AUTOSAR XML (schema 3.1.2)
package /Components/SWC_AFAT
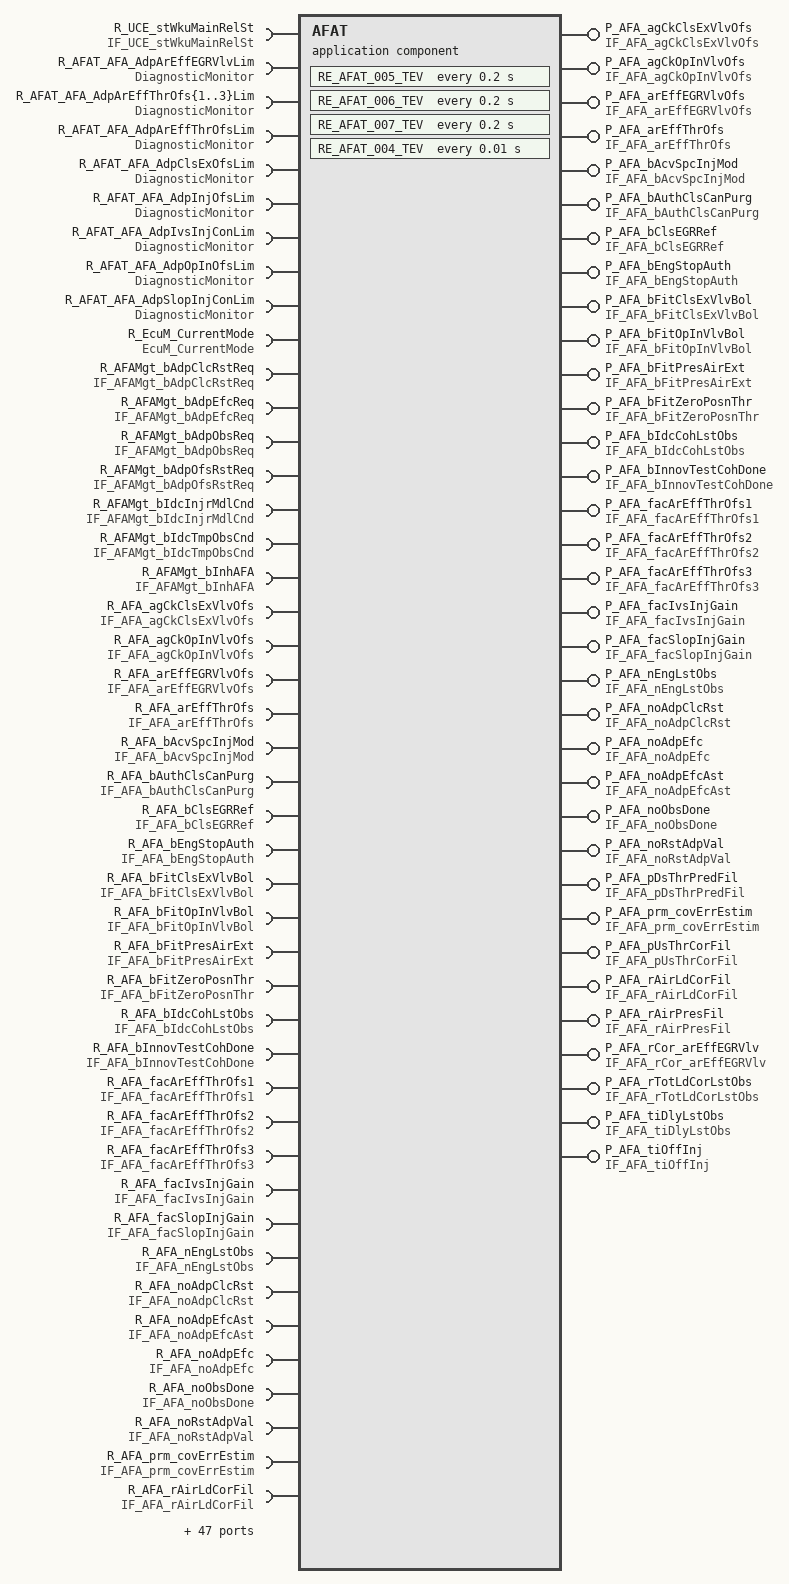
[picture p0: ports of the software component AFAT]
  application software component type AFAT
    11 x require port:
      R_UCE_stWkuMainRelSt: required-interface=IF_UCE_stWkuMainRelSt
      R_AFAT_AFA_AdpArEffEGRVlvLim: required-interface=DiagnosticMonitor
      R_AFAT_AFA_AdpArEffThrOfs{1..3}Lim: required-interface=DiagnosticMonitor
      R_AFAT_AFA_AdpArEffThrOfsLim: required-interface=DiagnosticMonitor
      R_AFAT_AFA_AdpClsExOfsLim: required-interface=DiagnosticMonitor
      R_AFAT_AFA_AdpInjOfsLim: required-interface=DiagnosticMonitor
      R_AFAT_AFA_AdpIvsInjConLim: required-interface=DiagnosticMonitor
      R_AFAT_AFA_AdpOpInOfsLim: required-interface=DiagnosticMonitor
      R_AFAT_AFA_AdpSlopInjConLim: required-interface=DiagnosticMonitor
    34 x provide port:
      P_AFA_agCkClsExVlvOfs: unqueued-sender-com-spec{data-element=AFA_agCkClsExVlvOfs, can-invalidate=false, init-value=SInt8InitValue}, provided-interface=IF_AFA_agCkClsExVlvOfs
      P_AFA_agCkOpInVlvOfs: unqueued-sender-com-spec{data-element=AFA_agCkOpInVlvOfs, can-invalidate=false, init-value=SInt8InitValue1}, provided-interface=IF_AFA_agCkOpInVlvOfs
      P_AFA_arEffEGRVlvOfs: unqueued-sender-com-spec{data-element=AFA_arEffEGRVlvOfs, can-invalidate=false, init-value=SInt8InitValue3}, provided-interface=IF_AFA_arEffEGRVlvOfs
      P_AFA_arEffThrOfs: unqueued-sender-com-spec{data-element=AFA_arEffThrOfs, can-invalidate=false, init-value=SInt16InitValue}, provided-interface=IF_AFA_arEffThrOfs
      P_AFA_bAcvSpcInjMod: unqueued-sender-com-spec{data-element=AFA_bAcvSpcInjMod, can-invalidate=false, init-value=BooleanInitValue}, provided-interface=IF_AFA_bAcvSpcInjMod
      P_AFA_bAuthClsCanPurg: unqueued-sender-com-spec{data-element=AFA_bAuthClsCanPurg, can-invalidate=false, init-value=BooleanInitValue5}, provided-interface=IF_AFA_bAuthClsCanPurg
      P_AFA_bClsEGRRef: unqueued-sender-com-spec{data-element=AFA_bClsEGRRef, can-invalidate=false, init-value=BooleanInitValue7}, provided-interface=IF_AFA_bClsEGRRef
      P_AFA_bEngStopAuth: unqueued-sender-com-spec{data-element=AFA_bEngStopAuth, can-invalidate=false, init-value=BooleanInitValue9}, provided-interface=IF_AFA_bEngStopAuth
      P_AFA_bFitClsExVlvBol: unqueued-sender-com-spec{data-element=AFA_bFitClsExVlvBol, can-invalidate=false, init-value=BooleanInitValue11}, provided-interface=IF_AFA_bFitClsExVlvBol
      P_AFA_bFitOpInVlvBol: unqueued-sender-com-spec{data-element=AFA_bFitOpInVlvBol, can-invalidate=false, init-value=BooleanInitValue13}, provided-interface=IF_AFA_bFitOpInVlvBol
      P_AFA_bFitPresAirExt: unqueued-sender-com-spec{data-element=AFA_bFitPresAirExt, can-invalidate=false, init-value=BooleanInitValue15}, provided-interface=IF_AFA_bFitPresAirExt
      P_AFA_bFitZeroPosnThr: unqueued-sender-com-spec{data-element=AFA_bFitZeroPosnThr, can-invalidate=false, init-value=BooleanInitValue17}, provided-interface=IF_AFA_bFitZeroPosnThr
      P_AFA_bIdcCohLstObs: unqueued-sender-com-spec{data-element=AFA_bIdcCohLstObs, can-invalidate=false, init-value=BooleanInitValue19}, provided-interface=IF_AFA_bIdcCohLstObs
      P_AFA_bInnovTestCohDone: unqueued-sender-com-spec{data-element=AFA_bInnovTestCohDone, can-invalidate=false, init-value=BooleanInitValue21}, provided-interface=IF_AFA_bInnovTestCohDone
      P_AFA_facArEffThrOfs1: unqueued-sender-com-spec{data-element=AFA_facArEffThrOfs1, can-invalidate=false, init-value=SInt8InitValue23}, provided-interface=IF_AFA_facArEffThrOfs1
      P_AFA_facArEffThrOfs2: unqueued-sender-com-spec{data-element=AFA_facArEffThrOfs2, can-invalidate=false, init-value=SInt8InitValue25}, provided-interface=IF_AFA_facArEffThrOfs2
      P_AFA_facArEffThrOfs3: unqueued-sender-com-spec{data-element=AFA_facArEffThrOfs3, can-invalidate=false, init-value=SInt8InitValue27}, provided-interface=IF_AFA_facArEffThrOfs3
      P_AFA_facIvsInjGain: unqueued-sender-com-spec{data-element=AFA_facIvsInjGain, can-invalidate=false, init-value=SInt16InitValue29}, provided-interface=IF_AFA_facIvsInjGain
      P_AFA_facSlopInjGain: unqueued-sender-com-spec{data-element=AFA_facSlopInjGain, can-invalidate=false, init-value=SInt32InitValue}, provided-interface=IF_AFA_facSlopInjGain
      P_AFA_nEngLstObs: unqueued-sender-com-spec{data-element=AFA_nEngLstObs, can-invalidate=false, init-value=UInt16InitValue}, provided-interface=IF_AFA_nEngLstObs
      P_AFA_noAdpClcRst: unqueued-sender-com-spec{data-element=AFA_noAdpClcRst, can-invalidate=false, init-value=UInt8InitValue}, provided-interface=IF_AFA_noAdpClcRst
      P_AFA_noAdpEfc: unqueued-sender-com-spec{data-element=AFA_noAdpEfc, can-invalidate=false, init-value=UInt16InitValue31}, provided-interface=IF_AFA_noAdpEfc
      P_AFA_noAdpEfcAst: unqueued-sender-com-spec{data-element=AFA_noAdpEfcAst, can-invalidate=false, init-value=UInt16InitValue33}, provided-interface=IF_AFA_noAdpEfcAst
      P_AFA_noObsDone: unqueued-sender-com-spec{data-element=AFA_noObsDone, can-invalidate=false, init-value=UInt8InitValue35}, provided-interface=IF_AFA_noObsDone
      P_AFA_noRstAdpVal: unqueued-sender-com-spec{data-element=AFA_noRstAdpVal, can-invalidate=false, init-value=UInt8InitValue37}, provided-interface=IF_AFA_noRstAdpVal
      P_AFA_pDsThrPredFil: unqueued-sender-com-spec{data-element=AFA_pDsThrPredFil, can-invalidate=false, init-value=UInt16InitValue39}, provided-interface=IF_AFA_pDsThrPredFil
      P_AFA_prm_covErrEstim: unqueued-sender-com-spec{data-element=AFA_prm_covErrEstim, can-invalidate=false, init-value=rt_Array_UInt16_8InitValue}, provided-interface=IF_AFA_prm_covErrEstim
      P_AFA_pUsThrCorFil: unqueued-sender-com-spec{data-element=AFA_pUsThrCorFil, can-invalidate=false, init-value=UInt16InitValue41}, provided-interface=IF_AFA_pUsThrCorFil
      P_AFA_rAirLdCorFil: unqueued-sender-com-spec{data-element=AFA_rAirLdCorFil, can-invalidate=false, init-value=UInt16InitValue43}, provided-interface=IF_AFA_rAirLdCorFil
      P_AFA_rAirPresFil: unqueued-sender-com-spec{data-element=AFA_rAirPresFil, can-invalidate=false, init-value=UInt16InitValue45}, provided-interface=IF_AFA_rAirPresFil
      P_AFA_rCor_arEffEGRVlv: unqueued-sender-com-spec{data-element=AFA_rCor_arEffEGRVlv, can-invalidate=false, init-value=SInt8InitValue47}, provided-interface=IF_AFA_rCor_arEffEGRVlv
      P_AFA_rTotLdCorLstObs: unqueued-sender-com-spec{data-element=AFA_rTotLdCorLstObs, can-invalidate=false, init-value=UInt16InitValue49}, provided-interface=IF_AFA_rTotLdCorLstObs
      P_AFA_tiDlyLstObs: unqueued-sender-com-spec{data-element=AFA_tiDlyLstObs, can-invalidate=false, init-value=UInt32InitValue}, provided-interface=IF_AFA_tiDlyLstObs
      P_AFA_tiOffInj: unqueued-sender-com-spec{data-element=AFA_tiOffInj, can-invalidate=false, init-value=SInt8InitValue51}, provided-interface=IF_AFA_tiOffInj
    82 x require port:
      R_EcuM_CurrentMode: required-interface=EcuM_CurrentMode
      R_AFAMgt_bAdpClcRstReq: unqueued-receiver-com-spec{data-element=AFAMgt_bAdpClcRstReq, init-value=BooleanInitValue53, resync-time=0}, required-interface=IF_AFAMgt_bAdpClcRstReq
      R_AFAMgt_bAdpEfcReq: unqueued-receiver-com-spec{data-element=AFAMgt_bAdpEfcReq, init-value=BooleanInitValue55, resync-time=0}, required-interface=IF_AFAMgt_bAdpEfcReq
      R_AFAMgt_bAdpObsReq: unqueued-receiver-com-spec{data-element=AFAMgt_bAdpObsReq, init-value=BooleanInitValue57, resync-time=0}, required-interface=IF_AFAMgt_bAdpObsReq
      R_AFAMgt_bAdpOfsRstReq: unqueued-receiver-com-spec{data-element=AFAMgt_bAdpOfsRstReq, init-value=BooleanInitValue59, resync-time=0}, required-interface=IF_AFAMgt_bAdpOfsRstReq
      R_AFAMgt_bIdcInjrMdlCnd: unqueued-receiver-com-spec{data-element=AFAMgt_bIdcInjrMdlCnd, init-value=BooleanInitValue61, resync-time=0}, required-interface=IF_AFAMgt_bIdcInjrMdlCnd
      R_AFAMgt_bIdcTmpObsCnd: unqueued-receiver-com-spec{data-element=AFAMgt_bIdcTmpObsCnd, init-value=BooleanInitValue63, resync-time=0}, required-interface=IF_AFAMgt_bIdcTmpObsCnd
      R_AFAMgt_bInhAFA: unqueued-receiver-com-spec{data-element=AFAMgt_bInhAFA, init-value=BooleanInitValue65, resync-time=0}, required-interface=IF_AFAMgt_bInhAFA
      R_AFA_agCkClsExVlvOfs: unqueued-receiver-com-spec{data-element=AFA_agCkClsExVlvOfs, init-value=SInt8InitValue, resync-time=0}, required-interface=IF_AFA_agCkClsExVlvOfs
      R_AFA_agCkOpInVlvOfs: unqueued-receiver-com-spec{data-element=AFA_agCkOpInVlvOfs, init-value=SInt8InitValue67, resync-time=0}, required-interface=IF_AFA_agCkOpInVlvOfs
      R_AFA_arEffEGRVlvOfs: unqueued-receiver-com-spec{data-element=AFA_arEffEGRVlvOfs, init-value=SInt8InitValue69, resync-time=0}, required-interface=IF_AFA_arEffEGRVlvOfs
      R_AFA_arEffThrOfs: unqueued-receiver-com-spec{data-element=AFA_arEffThrOfs, init-value=SInt16InitValue, resync-time=0}, required-interface=IF_AFA_arEffThrOfs
      R_AFA_bAcvSpcInjMod: unqueued-receiver-com-spec{data-element=AFA_bAcvSpcInjMod, init-value=BooleanInitValue, resync-time=0}, required-interface=IF_AFA_bAcvSpcInjMod
      R_AFA_bAuthClsCanPurg: unqueued-receiver-com-spec{data-element=AFA_bAuthClsCanPurg, init-value=BooleanInitValue71, resync-time=0}, required-interface=IF_AFA_bAuthClsCanPurg
      R_AFA_bClsEGRRef: unqueued-receiver-com-spec{data-element=AFA_bClsEGRRef, init-value=BooleanInitValue73, resync-time=0}, required-interface=IF_AFA_bClsEGRRef
      R_AFA_bEngStopAuth: unqueued-receiver-com-spec{data-element=AFA_bEngStopAuth, init-value=ConstantValue, resync-time=0}, required-interface=IF_AFA_bEngStopAuth
      R_AFA_bFitClsExVlvBol: unqueued-receiver-com-spec{data-element=AFA_bFitClsExVlvBol, init-value=BooleanInitValue75, resync-time=0}, required-interface=IF_AFA_bFitClsExVlvBol
      R_AFA_bFitOpInVlvBol: unqueued-receiver-com-spec{data-element=AFA_bFitOpInVlvBol, init-value=BooleanInitValue77, resync-time=0}, required-interface=IF_AFA_bFitOpInVlvBol
      R_AFA_bFitPresAirExt: unqueued-receiver-com-spec{data-element=AFA_bFitPresAirExt, init-value=BooleanInitValue79, resync-time=0}, required-interface=IF_AFA_bFitPresAirExt
      R_AFA_bFitZeroPosnThr: unqueued-receiver-com-spec{data-element=AFA_bFitZeroPosnThr, init-value=BooleanInitValue81, resync-time=0}, required-interface=IF_AFA_bFitZeroPosnThr
      R_AFA_bIdcCohLstObs: unqueued-receiver-com-spec{data-element=AFA_bIdcCohLstObs, init-value=BooleanInitValue83, resync-time=0}, required-interface=IF_AFA_bIdcCohLstObs
      R_AFA_bInnovTestCohDone: unqueued-receiver-com-spec{data-element=AFA_bInnovTestCohDone, init-value=BooleanInitValue85, resync-time=0}, required-interface=IF_AFA_bInnovTestCohDone
      R_AFA_facArEffThrOfs1: unqueued-receiver-com-spec{data-element=AFA_facArEffThrOfs1, init-value=SInt8InitValue87, resync-time=0}, required-interface=IF_AFA_facArEffThrOfs1
      R_AFA_facArEffThrOfs2: unqueued-receiver-com-spec{data-element=AFA_facArEffThrOfs2, init-value=SInt8InitValue89, resync-time=0}, required-interface=IF_AFA_facArEffThrOfs2
      R_AFA_facArEffThrOfs3: unqueued-receiver-com-spec{data-element=AFA_facArEffThrOfs3, init-value=SInt8InitValue91, resync-time=0}, required-interface=IF_AFA_facArEffThrOfs3
      R_AFA_facIvsInjGain: unqueued-receiver-com-spec{data-element=AFA_facIvsInjGain, init-value=SInt16InitValue93, resync-time=0}, required-interface=IF_AFA_facIvsInjGain
      R_AFA_facSlopInjGain: unqueued-receiver-com-spec{data-element=AFA_facSlopInjGain, init-value=SInt32InitValue, resync-time=0}, required-interface=IF_AFA_facSlopInjGain
      R_AFA_nEngLstObs: unqueued-receiver-com-spec{data-element=AFA_nEngLstObs, init-value=UInt16InitValue, resync-time=0}, required-interface=IF_AFA_nEngLstObs
      R_AFA_noAdpClcRst: unqueued-receiver-com-spec{data-element=AFA_noAdpClcRst, init-value=UInt8InitValue, resync-time=0}, required-interface=IF_AFA_noAdpClcRst
      R_AFA_noAdpEfcAst: unqueued-receiver-com-spec{data-element=AFA_noAdpEfcAst, init-value=UInt16InitValue95, resync-time=0}, required-interface=IF_AFA_noAdpEfcAst
      R_AFA_noAdpEfc: unqueued-receiver-com-spec{data-element=AFA_noAdpEfc, init-value=UInt16InitValue97, resync-time=0}, required-interface=IF_AFA_noAdpEfc
      R_AFA_noObsDone: unqueued-receiver-com-spec{data-element=AFA_noObsDone, init-value=UInt8InitValue99, resync-time=0}, required-interface=IF_AFA_noObsDone
      R_AFA_noRstAdpVal: unqueued-receiver-com-spec{data-element=AFA_noRstAdpVal, init-value=UInt8InitValue101, resync-time=0}, required-interface=IF_AFA_noRstAdpVal
      R_AFA_prm_covErrEstim: unqueued-receiver-com-spec{data-element=AFA_prm_covErrEstim, init-value=rt_Array_UInt16_8InitValue, resync-time=0}, required-interface=IF_AFA_prm_covErrEstim
      R_AFA_rAirLdCorFil: unqueued-receiver-com-spec{data-element=AFA_rAirLdCorFil, init-value=UInt16InitValue103, resync-time=0}, required-interface=IF_AFA_rAirLdCorFil
      R_AFA_rAirPresFil: unqueued-receiver-com-spec{data-element=AFA_rAirPresFil, init-value=UInt16InitValue105, resync-time=0}, required-interface=IF_AFA_rAirPresFil
      R_AFA_rCor_arEffEGRVlv: unqueued-receiver-com-spec{data-element=AFA_rCor_arEffEGRVlv, init-value=SInt8InitValue107, resync-time=0}, required-interface=IF_AFA_rCor_arEffEGRVlv
      R_AFA_rTotLdCorLstObs: unqueued-receiver-com-spec{data-element=AFA_rTotLdCorLstObs, init-value=UInt16InitValue109, resync-time=0}, required-interface=IF_AFA_rTotLdCorLstObs
      R_AFA_tiDlyLstObs: unqueued-receiver-com-spec{data-element=AFA_tiDlyLstObs, init-value=UInt32InitValue, resync-time=0}, required-interface=IF_AFA_tiDlyLstObs
      R_AFA_tiOffInj: unqueued-receiver-com-spec{data-element=AFA_tiOffInj, init-value=SInt8InitValue111, resync-time=0}, required-interface=IF_AFA_tiOffInj
      R_AfuA_rEthStoich: unqueued-receiver-com-spec{data-element=AfuA_rEthStoich, init-value=UInt16InitValue113, resync-time=0}, required-interface=IF_AfuA_rEthStoich
      R_EGRVlv_rOpClsEGRVlvBol: unqueued-receiver-com-spec{data-element=EGRVlv_rOpClsEGRVlvBol, init-value=UInt32InitValue115, resync-time=0}, required-interface=IF_EGRVlv_rOpClsEGRVlvBol
      R_EngM_agCkClsExVlvEstimRef1: unqueued-receiver-com-spec{data-element=EngM_agCkClsExVlvEstimRef1, init-value=SInt16InitValue117, resync-time=0}, required-interface=IF_EngM_agCkClsExVlvEstimRef1
      R_EngM_agCkClsInVlvEstimRef1: unqueued-receiver-com-spec{data-element=EngM_agCkClsInVlvEstimRef1, init-value=UInt16InitValue119, resync-time=0}, required-interface=IF_EngM_agCkClsInVlvEstimRef1
      R_EngM_agCkOpInVlvEstimRef1: unqueued-receiver-com-spec{data-element=EngM_agCkOpInVlvEstimRef1, init-value=SInt16InitValue121, resync-time=0}, required-interface=IF_EngM_agCkOpInVlvEstimRef1
      R_EngM_facSlopEfcCor: unqueued-receiver-com-spec{data-element=EngM_facSlopEfcCor, init-value=UInt16InitValue123, resync-time=0}, required-interface=IF_EngM_facSlopEfcCor
      R_EngM_rAirLdCor: unqueued-receiver-com-spec{data-element=EngM_rAirLdCor, init-value=UInt16InitValue125, resync-time=0}, required-interface=IF_EngM_rAirLdCor
      R_EngM_rTotLdExCor: unqueued-receiver-com-spec{data-element=EngM_rTotLdExCor, init-value=UInt16InitValue127, resync-time=0}, required-interface=IF_EngM_rTotLdExCor
      R_EOM_bSpcInjMod: unqueued-receiver-com-spec{data-element=EOM_bSpcInjMod, init-value=BooleanInitValue129, resync-time=0}, required-interface=IF_EOM_bSpcInjMod
      R_ExM_pExMnfEstim_facVlvOvlp: unqueued-receiver-com-spec{data-element=ExM_pExMnfEstim_facVlvOvlp, init-value=UInt16InitValue131, resync-time=0}, required-interface=IF_ExM_pExMnfEstim_facVlvOvlp
      R_ExM_tExMnfEstim: unqueued-receiver-com-spec{data-element=ExM_tExMnfEstim, init-value=UInt16InitValue133, resync-time=0}, required-interface=IF_ExM_tExMnfEstim
      R_Ext_facRhoFu: unqueued-receiver-com-spec{data-element=Ext_facRhoFu, init-value=UInt8InitValue135, resync-time=0}, required-interface=IF_Ext_facRhoFu
      R_Ext_nEng: unqueued-receiver-com-spec{data-element=Ext_nEng, init-value=UInt16InitValue137, resync-time=0}, required-interface=IF_Ext_nEng
      R_Ext_tCoMes: unqueued-receiver-com-spec{data-element=Ext_tCoMes, init-value=SInt16InitValue139, resync-time=0}, required-interface=IF_Ext_tCoMes
      R_IdlSys_bAcvIdlCtl: unqueued-receiver-com-spec{data-element=IdlSys_bAcvIdlCtl, init-value=BooleanInitValue141, resync-time=0}, required-interface=IF_IdlSys_bAcvIdlCtl
      R_InjrM_prm_facCorGainLnr: unqueued-receiver-com-spec{data-element=InjrM_prm_facCorGainLnr, init-value=rt_Array_UInt16_4InitValue, resync-time=0}, required-interface=IF_InjrM_prm_facCorGainLnr
      R_InjrM_prm_facGainInj: unqueued-receiver-com-spec{data-element=InjrM_prm_facGainInj, init-value=rt_Array_UInt16_4InitValue143, resync-time=0}, required-interface=IF_InjrM_prm_facGainInj
      R_InjrM_prm_pDifInjr: unqueued-receiver-com-spec{data-element=InjrM_prm_pDifInjr, init-value=rt_Array_UInt16_4InitValue145, resync-time=0}, required-interface=IF_InjrM_prm_pDifInjr
      R_InjrSys_prm_tiInj: unqueued-receiver-com-spec{data-element=InjrSys_prm_tiInj, init-value=rt_Array_UInt32_4InitValue, resync-time=0}, required-interface=IF_InjrSys_prm_tiInj
      R_InjSys_lamFbFil: unqueued-receiver-com-spec{data-element=InjSys_lamFbFil, init-value=SInt32InitValue147, resync-time=0}, required-interface=IF_InjSys_lamFbFil
      R_InjSys_mFuReq: unqueued-receiver-com-spec{data-element=InjSys_mFuReq, init-value=UInt32InitValue149, resync-time=0}, required-interface=IF_InjSys_mFuReq
      R_InjSys_noTDCDlyLsclFilMod: unqueued-receiver-com-spec{data-element=InjSys_noTDCDlyLsclFilMod, init-value=UInt8InitValue151, resync-time=0}, required-interface=IF_InjSys_noTDCDlyLsclFilMod
      R_InM_arEffAdpEGRVlv: unqueued-receiver-com-spec{data-element=InM_arEffAdpEGRVlv, init-value=UInt16InitValue153, resync-time=0}, required-interface=IF_InM_arEffAdpEGRVlv
      R_InM_arEffAdpThr: unqueued-receiver-com-spec{data-element=InM_arEffAdpThr, init-value=UInt16InitValue155, resync-time=0}, required-interface=IF_InM_arEffAdpThr
      R_InM_arEffEGRVlv: unqueued-receiver-com-spec{data-element=InM_arEffEGRVlv, init-value=UInt16InitValue157, resync-time=0}, required-interface=IF_InM_arEffEGRVlv
      R_InM_mfAirThrEstim: unqueued-receiver-com-spec{data-element=InM_mfAirThrEstim, init-value=UInt16InitValue159, resync-time=0}, required-interface=IF_InM_mfAirThrEstim
      R_InM_mfEGREstimEGRVlv: unqueued-receiver-com-spec{data-element=InM_mfEGREstimEGRVlv, init-value=UInt16InitValue161, resync-time=0}, required-interface=IF_InM_mfEGREstimEGRVlv
      R_InM_pDsThrCor: unqueued-receiver-com-spec{data-element=InM_pDsThrCor, init-value=UInt16InitValue163, resync-time=0}, required-interface=IF_InM_pDsThrCor
      R_InM_pDsThrEstim: unqueued-receiver-com-spec{data-element=InM_pDsThrEstim, init-value=UInt32InitValue165, resync-time=0}, required-interface=IF_InM_pDsThrEstim
      R_InM_pDsThrEstimErr: unqueued-receiver-com-spec{data-element=InM_pDsThrEstimErr, init-value=SInt16InitValue167, resync-time=0}, required-interface=IF_InM_pDsThrEstimErr
      R_InM_pDsThrPred: unqueued-receiver-com-spec{data-element=InM_pDsThrPred, init-value=UInt16InitValue169, resync-time=0}, required-interface=IF_InM_pDsThrPred
      R_InM_pDsThrPred_facVlvOvlp: unqueued-receiver-com-spec{data-element=InM_pDsThrPred_facVlvOvlp, init-value=UInt16InitValue171, resync-time=0}, required-interface=IF_InM_pDsThrPred_facVlvOvlp
      R_InM_rAirPres: unqueued-receiver-com-spec{data-element=InM_rAirPres, init-value=UInt16InitValue173, resync-time=0}, required-interface=IF_InM_rAirPres
      R_InThM_nEngCor: unqueued-receiver-com-spec{data-element=InThM_nEngCor, init-value=UInt16InitValue175, resync-time=0}, required-interface=IF_InThM_nEngCor
      R_InThM_tAirUsInVlvEstim: unqueued-receiver-com-spec{data-element=InThM_tAirUsInVlvEstim, init-value=UInt16InitValue177, resync-time=0}, required-interface=IF_InThM_tAirUsInVlvEstim
      R_ThrLrn_rOpClsThrBol: unqueued-receiver-com-spec{data-element=ThrLrn_rOpClsThrBol, init-value=UInt16InitValue179, resync-time=0}, required-interface=IF_ThrLrn_rOpClsThrBol
      R_ThrLrn_rOpSI: unqueued-receiver-com-spec{data-element=ThrLrn_rOpSI, init-value=UInt16InitValue181, resync-time=0}, required-interface=IF_ThrLrn_rOpSI
      R_UsThrM_pAirExt: unqueued-receiver-com-spec{data-element=UsThrM_pAirExt, init-value=UInt16InitValue183, resync-time=0}, required-interface=IF_UsThrM_pAirExt
      R_UsThrM_pAirExtEstim: unqueued-receiver-com-spec{data-element=UsThrM_pAirExtEstim, init-value=UInt16InitValue185, resync-time=0}, required-interface=IF_UsThrM_pAirExtEstim
      R_UsThrM_pUsThrCor: unqueued-receiver-com-spec{data-element=UsThrM_pUsThrCor, init-value=UInt16InitValue187, resync-time=0}, required-interface=IF_UsThrM_pUsThrCor
      R_VlvAct_prm_agCkClsExVlvBol: unqueued-receiver-com-spec{data-element=VlvAct_prm_agCkClsExVlvBol, init-value=rt_Array_UInt16_4InitValue189, resync-time=0}, required-interface=IF_VlvAct_prm_agCkClsExVlvBol
      R_VlvAct_prm_agCkOpInVlvBol: unqueued-receiver-com-spec{data-element=VlvAct_prm_agCkOpInVlvBol, init-value=rt_Array_UInt16_4InitValue191, resync-time=0}, required-interface=IF_VlvAct_prm_agCkOpInVlvBol
  141 x constant specification:
    BooleanInitValue
      value:
        boolean literal BooleanInitValue: type=DT_AFA_bAcvSpcInjMod, value=false
    BooleanInitValue11
      value:
        boolean literal BooleanInitValue11: type=DT_AFA_bFitClsExVlvBol, value=false
    BooleanInitValue129
      value:
        boolean literal BooleanInitValue129: type=DT_EOM_bSpcInjMod, value=false
    BooleanInitValue13
      value:
        boolean literal BooleanInitValue13: type=DT_AFA_bFitOpInVlvBol, value=false
    BooleanInitValue141
      value:
        boolean literal BooleanInitValue141: type=DT_IdlSys_bAcvIdlCtl, value=false
    BooleanInitValue15
      value:
        boolean literal BooleanInitValue15: type=DT_AFA_bFitPresAirExt, value=false
    BooleanInitValue17
      value:
        boolean literal BooleanInitValue17: type=DT_AFA_bFitZeroPosnThr, value=false
    BooleanInitValue19
      value:
        boolean literal BooleanInitValue19: type=DT_AFA_bIdcCohLstObs, value=false
    BooleanInitValue21
      value:
        boolean literal BooleanInitValue21: type=DT_AFA_bInnovTestCohDone, value=false
    BooleanInitValue239
      value:
        boolean literal BooleanInitValue239: type=DT_AFA_bIdcInv_covPredInnov_irv, value=false
    BooleanInitValue255
      value:
        boolean literal BooleanInitValue255: type=DT_AFA_bAdpClcRstReqHld_irv, value=false
    BooleanInitValue5
      value:
        boolean literal BooleanInitValue5: type=DT_AFA_bAuthClsCanPurg, value=false
    BooleanInitValue53
      value:
        boolean literal BooleanInitValue53: type=DT_AFAMgt_bAdpClcRstReq, value=false
    BooleanInitValue55
      value:
        boolean literal BooleanInitValue55: type=DT_AFAMgt_bAdpEfcReq, value=false
    BooleanInitValue57
      value:
        boolean literal BooleanInitValue57: type=DT_AFAMgt_bAdpObsReq, value=false
    BooleanInitValue59
      value:
        boolean literal BooleanInitValue59: type=DT_AFAMgt_bAdpOfsRstReq, value=false
    BooleanInitValue61
      value:
        boolean literal BooleanInitValue61: type=DT_AFAMgt_bIdcInjrMdlCnd, value=false
    BooleanInitValue63
      value:
        boolean literal BooleanInitValue63: type=DT_AFAMgt_bIdcTmpObsCnd, value=false
    BooleanInitValue65
      value:
        boolean literal BooleanInitValue65: type=DT_AFAMgt_bInhAFA, value=false
    BooleanInitValue7
      value:
        boolean literal BooleanInitValue7: type=DT_AFA_bClsEGRRef, value=false
    BooleanInitValue71
      value:
        boolean literal BooleanInitValue71: type=DT_AFA_bAuthClsCanPurg, value=false
    BooleanInitValue73
      value:
        boolean literal BooleanInitValue73: type=DT_AFA_bClsEGRRef, value=false
    BooleanInitValue75
      value:
        boolean literal BooleanInitValue75: type=DT_AFA_bFitClsExVlvBol, value=false
    BooleanInitValue77
      value:
        boolean literal BooleanInitValue77: type=DT_AFA_bFitOpInVlvBol, value=false
    BooleanInitValue79
      value:
        boolean literal BooleanInitValue79: type=DT_AFA_bFitPresAirExt, value=false
    BooleanInitValue81
      value:
        boolean literal BooleanInitValue81: type=DT_AFA_bFitZeroPosnThr, value=false
    BooleanInitValue83
      value:
        boolean literal BooleanInitValue83: type=DT_AFA_bIdcCohLstObs, value=false
    BooleanInitValue85
      value:
        boolean literal BooleanInitValue85: type=DT_AFA_bInnovTestCohDone, value=false
    BooleanInitValue9
      value:
        boolean literal BooleanInitValue9: type=DT_AFA_bEngStopAuth, value=false
    ConstantValue
      value:
        boolean literal ConstantValue: type=DT_AFA_bEngStopAuth, value=false
    rt_Array_UInt16_4InitValue
      value:
        array specification rt_Array_UInt16_4InitValue: type=rt_Array_UInt16_4_m3
          4 x integer literal, all with type=DT_InjrM_prm_facCorGainLnr, value=0:
            UInt16_{1..4}
    rt_Array_UInt16_4InitValue143
      value:
        array specification rt_Array_UInt16_4InitValue143: type=rt_Array_UInt16_4_m2
          4 x integer literal, all with type=DT_InjrM_prm_facGainInj, value=0:
            UInt16_{1..4}
    rt_Array_UInt16_4InitValue145
      value:
        array specification rt_Array_UInt16_4InitValue145: type=rt_Array_UInt16_4_m4
          4 x integer literal, all with type=DT_InjrM_prm_pDifInjr, value=0:
            UInt16_{1..4}
    rt_Array_UInt16_4InitValue189
      value:
        array specification rt_Array_UInt16_4InitValue189: type=rt_Array_UInt16_4_m1
          4 x integer literal, all with type=DT_VlvAct_prm_agCkClsExVlvBol, value=0:
            UInt16_{1..4}
    rt_Array_UInt16_4InitValue191
      value:
        array specification rt_Array_UInt16_4InitValue191: type=rt_Array_UInt16_4_m0
          4 x integer literal, all with type=DT_VlvAct_prm_agCkOpInVlvBol, value=0:
            UInt16_{1..4}
    rt_Array_UInt16_8InitValue
      value:
        array specification rt_Array_UInt16_8InitValue: type=rt_Array_UInt16_8_m0
          8 x integer literal, all with type=DT_AFA_prm_covErrEstim, value=0:
            UInt16_{1..8}
    rt_Array_UInt32_4InitValue
      value:
        array specification rt_Array_UInt32_4InitValue: type=Array_4_UInt32
          4 x integer literal, all with type=DT_InjrSys_prm_tiInj, value=0:
            UInt32_{1..4}
    SInt16InitValue
      value:
        integer literal SInt16InitValue: type=DT_AFA_arEffThrOfs, value=0
    SInt16InitValue117
      value:
        integer literal SInt16InitValue117: type=DT_EngM_agCkClsExVlvEstimRef1, value=0
    SInt16InitValue121
      value:
        integer literal SInt16InitValue121: type=DT_EngM_agCkOpInVlvEstimRef1, value=0
    SInt16InitValue139
      value:
        integer literal SInt16InitValue139: type=DT_Ext_tCoMes, value=20
    SInt16InitValue167
      value:
        integer literal SInt16InitValue167: type=DT_InM_pDsThrEstimErr, value=0
    SInt16InitValue193
      value:
        integer literal SInt16InitValue193: type=DT_AFA_agCkOpInVlvEstimRef1Fil_irv, value=0
    SInt16InitValue213
      value:
        integer literal SInt16InitValue213: type=DT_AFA_tCoMesFil_irv, value=0
    SInt16InitValue217
      value:
        integer literal SInt16InitValue217: type=DT_AFA_agCkClsExVlvEstimRef1Fil_irv, value=0
    SInt16InitValue237
      value:
        integer literal SInt16InitValue237: type=DT_AFA_pDsThrEstimErrFil_irv, value=0
    SInt16InitValue29
      value:
        integer literal SInt16InitValue29: type=DT_AFA_facIvsInjGain, value=-32768
    SInt16InitValue93
      value:
        integer literal SInt16InitValue93: type=DT_AFA_facIvsInjGain, value=-32768
    SInt32InitValue
      value:
        integer literal SInt32InitValue: type=DT_AFA_facSlopInjGain, value=-137438953
    SInt32InitValue147
      value:
        integer literal SInt32InitValue147: type=DT_InjSys_lamFbFil, value=-65536
    SInt8InitValue
      value:
        integer literal SInt8InitValue: type=DT_AFA_agCkClsExVlvOfs, value=0
    SInt8InitValue1
      value:
        integer literal SInt8InitValue1: type=DT_AFA_agCkOpInVlvOfs, value=0
    SInt8InitValue107
      value:
        integer literal SInt8InitValue107: type=DT_AFA_rCor_arEffEGRVlv, value=0
    SInt8InitValue111
      value:
        integer literal SInt8InitValue111: type=DT_AFA_tiOffInj, value=-128
    SInt8InitValue23
      value:
        integer literal SInt8InitValue23: type=DT_AFA_facArEffThrOfs1, value=0
    SInt8InitValue25
      value:
        integer literal SInt8InitValue25: type=DT_AFA_facArEffThrOfs2, value=0
    SInt8InitValue27
      value:
        integer literal SInt8InitValue27: type=DT_AFA_facArEffThrOfs3, value=0
    SInt8InitValue3
      value:
        integer literal SInt8InitValue3: type=DT_AFA_arEffEGRVlvOfs, value=0
    SInt8InitValue47
      value:
        integer literal SInt8InitValue47: type=DT_AFA_rCor_arEffEGRVlv, value=0
    SInt8InitValue51
      value:
        integer literal SInt8InitValue51: type=DT_AFA_tiOffInj, value=-128
    SInt8InitValue67
      value:
        integer literal SInt8InitValue67: type=DT_AFA_agCkOpInVlvOfs, value=0
    SInt8InitValue69
      value:
        integer literal SInt8InitValue69: type=DT_AFA_arEffEGRVlvOfs, value=0
    SInt8InitValue87
      value:
        integer literal SInt8InitValue87: type=DT_AFA_facArEffThrOfs1, value=0
    SInt8InitValue89
      value:
        integer literal SInt8InitValue89: type=DT_AFA_facArEffThrOfs2, value=0
    SInt8InitValue91
      value:
        integer literal SInt8InitValue91: type=DT_AFA_facArEffThrOfs3, value=0
    UInt16InitValue
      value:
        integer literal UInt16InitValue: type=DT_AFA_nEngLstObs, value=0
    UInt16InitValue103
      value:
        integer literal UInt16InitValue103: type=DT_AFA_rAirLdCorFil, value=0
    UInt16InitValue105
      value:
        integer literal UInt16InitValue105: type=DT_AFA_rAirPresFil, value=0
    UInt16InitValue109
      value:
        integer literal UInt16InitValue109: type=DT_AFA_rTotLdCorLstObs, value=0
    UInt16InitValue113
      value:
        integer literal UInt16InitValue113: type=DT_AfuA_rEthStoich, value=32768
    UInt16InitValue119
      value:
        integer literal UInt16InitValue119: type=DT_EngM_agCkClsInVlvEstimRef1, value=0
    UInt16InitValue123
      value:
        integer literal UInt16InitValue123: type=DT_EngM_facSlopEfcCor, value=0
    UInt16InitValue125
      value:
        integer literal UInt16InitValue125: type=DT_EngM_rAirLdCor, value=0
    UInt16InitValue127
      value:
        integer literal UInt16InitValue127: type=DT_EngM_rTotLdExCor, value=0
    UInt16InitValue131
      value:
        integer literal UInt16InitValue131: type=DT_ExM_pExMnfEstim_facVlvOvlp, value=0
    UInt16InitValue133
      value:
        integer literal UInt16InitValue133: type=DT_ExM_tExMnfEstim, value=4800
    UInt16InitValue137
      value:
        integer literal UInt16InitValue137: type=DT_Ext_nEng, value=0
    UInt16InitValue153
      value:
        integer literal UInt16InitValue153: type=DT_InM_arEffAdpEGRVlv, value=0
    UInt16InitValue155
      value:
        integer literal UInt16InitValue155: type=DT_InM_arEffAdpThr, value=0
    UInt16InitValue157
      value:
        integer literal UInt16InitValue157: type=DT_InM_arEffEGRVlv, value=0
    UInt16InitValue159
      value:
        integer literal UInt16InitValue159: type=DT_InM_mfAirThrEstim, value=0
    UInt16InitValue161
      value:
        integer literal UInt16InitValue161: type=DT_InM_mfEGREstimEGRVlv, value=0
    UInt16InitValue163
      value:
        integer literal UInt16InitValue163: type=DT_InM_pDsThrCor, value=0
    UInt16InitValue169
      value:
        integer literal UInt16InitValue169: type=DT_InM_pDsThrPred, value=0
    UInt16InitValue171
      value:
        integer literal UInt16InitValue171: type=DT_InM_pDsThrPred_facVlvOvlp, value=0
    UInt16InitValue173
      value:
        integer literal UInt16InitValue173: type=DT_InM_rAirPres, value=58982
    UInt16InitValue175
      value:
        integer literal UInt16InitValue175: type=DT_InThM_nEngCor, value=0
    UInt16InitValue177
      value:
        integer literal UInt16InitValue177: type=DT_InThM_tAirUsInVlvEstim, value=0
    UInt16InitValue179
      value:
        integer literal UInt16InitValue179: type=DT_ThrLrn_rOpClsThrBol, value=0
    UInt16InitValue181
      value:
        integer literal UInt16InitValue181: type=DT_ThrLrn_rOpSI, value=0
    UInt16InitValue183
      value:
        integer literal UInt16InitValue183: type=DT_UsThrM_pAirExt, value=0
    UInt16InitValue185
      value:
        integer literal UInt16InitValue185: type=DT_UsThrM_pAirExtEstim, value=0
    UInt16InitValue187
      value:
        integer literal UInt16InitValue187: type=DT_UsThrM_pUsThrCor, value=0
    UInt16InitValue199
      value:
        integer literal UInt16InitValue199: type=DT_AFA_arEffAdpEGRVlvFil_irv, value=0
    UInt16InitValue201
      value:
        integer literal UInt16InitValue201: type=DT_AFA_pAirExtEstimHld_irv, value=0
    UInt16InitValue203
      value:
        integer literal UInt16InitValue203: type=DT_AFA_agCkOpInVlvBolHld_irv, value=0
    UInt16InitValue205
      value:
        integer literal UInt16InitValue205: type=DT_AFA_rTotLdExCorFil_irv, value=0
    UInt16InitValue209
      value:
        integer literal UInt16InitValue209: type=DT_AFA_agCkClsInVlvEstimRef1Fil_irv, value=0
    UInt16InitValue215
      value:
        integer literal UInt16InitValue215: type=DT_AFA_rOpClsEGRVlvBolHld_irv, value=0
    UInt16InitValue219
      value:
        integer literal UInt16InitValue219: type=DT_AFA_tExMnfEstimFil_irv, value=0
    UInt16InitValue221
      value:
        integer literal UInt16InitValue221: type=DT_AFA_arEffEGRVlvFil_irv, value=0
    UInt16InitValue223
      value:
        integer literal UInt16InitValue223: type=DT_AFA_agCkClsExVlvBolHld_irv, value=0
    UInt16InitValue225
      value:
        integer literal UInt16InitValue225: type=DT_AFA_arEffAdpThrFil_irv, value=0
    UInt16InitValue227
      value:
        integer literal UInt16InitValue227: type=DT_AFA_pExMnfEstimFil_irv, value=0
    UInt16InitValue229
      value:
        integer literal UInt16InitValue229: type=DT_AFA_nEngFil_irv, value=0
    UInt16InitValue231
      value:
        integer literal UInt16InitValue231: type=DT_AFA_rOpSIFil_irv, value=0
    UInt16InitValue233
      value:
        integer literal UInt16InitValue233: type=DT_AFA_nEngCorFil_irv, value=0
    UInt16InitValue235
      value:
        integer literal UInt16InitValue235: type=DT_AFA_pDsThrEstimFil_irv, value=0
    UInt16InitValue241
      value:
        integer literal UInt16InitValue241: type=DT_AFA_rOpClsThrBolHld_irv, value=0
    UInt16InitValue247
      value:
        integer literal UInt16InitValue247: type=DT_AFA_pDsThrPred_facVlvOvlpFil_irv, value=0
    UInt16InitValue249
      value:
        integer literal UInt16InitValue249: type=DT_AFA_rEthStoichFil_irv, value=0
    UInt16InitValue253
      value:
        integer literal UInt16InitValue253: type=DT_AFA_rInMassFlowFil_irv, value=0
    UInt16InitValue257
      value:
        integer literal UInt16InitValue257: type=DT_AFA_pDsThrCorFil_irv, value=0
    UInt16InitValue259
      value:
        integer literal UInt16InitValue259: type=DT_AFA_pAirExtEstimFil_irv, value=0
    UInt16InitValue31
      value:
        integer literal UInt16InitValue31: type=DT_AFA_noAdpEfc, value=0
    UInt16InitValue33
      value:
        integer literal UInt16InitValue33: type=DT_AFA_noAdpEfcAst, value=0
    UInt16InitValue39
      value:
        integer literal UInt16InitValue39: type=DT_AFA_pDsThrPredFil, value=0
    UInt16InitValue41
      value:
        integer literal UInt16InitValue41: type=DT_AFA_pUsThrCorFil, value=0
    UInt16InitValue43
      value:
        integer literal UInt16InitValue43: type=DT_AFA_rAirLdCorFil, value=0
    UInt16InitValue45
      value:
        integer literal UInt16InitValue45: type=DT_AFA_rAirPresFil, value=0
    UInt16InitValue49
      value:
        integer literal UInt16InitValue49: type=DT_AFA_rTotLdCorLstObs, value=0
    UInt16InitValue95
      value:
        integer literal UInt16InitValue95: type=DT_AFA_noAdpEfcAst, value=0
    UInt16InitValue97
      value:
        integer literal UInt16InitValue97: type=DT_AFA_noAdpEfc, value=0
    UInt32InitValue
      value:
        integer literal UInt32InitValue: type=DT_AFA_tiDlyLstObs, value=0
    UInt32InitValue115
      value:
        integer literal UInt32InitValue115: type=DT_EGRVlv_rOpClsEGRVlvBol, value=0
    UInt32InitValue149
      value:
        integer literal UInt32InitValue149: type=DT_InjSys_mFuReq, value=0
    UInt32InitValue165
      value:
        integer literal UInt32InitValue165: type=DT_InM_pDsThrEstim, value=0
    UInt32InitValue195
      value:
        integer literal UInt32InitValue195: type=DT_AFA_tAirUsInVlvEstimFil_irv, value=0
    UInt32InitValue243
      value:
        integer literal UInt32InitValue243: type=DT_AFA_facSlopEfcCorFil_irv, value=0
    UInt32InitValue245
      value:
        integer literal UInt32InitValue245: type=DT_AFA_mFuReqFil_irv, value=0
    UInt8InitValue
      value:
        integer literal UInt8InitValue: type=DT_AFA_noAdpClcRst, value=0
    UInt8InitValue101
      value:
        integer literal UInt8InitValue101: type=DT_AFA_noRstAdpVal, value=0
    UInt8InitValue135
      value:
        integer literal UInt8InitValue135: type=DT_Ext_facRhoFu, value=127
    UInt8InitValue151
      value:
        integer literal UInt8InitValue151: type=DT_InjSys_noTDCDlyLsclFilMod, value=0
    UInt8InitValue197
      value:
        integer literal UInt8InitValue197: type=DT_AFA_noObsInnovNotCoh_irv, value=0
    UInt8InitValue207
      value:
        integer literal UInt8InitValue207: type=DT_AFA_facRhoFuFil_irv, value=0
    UInt8InitValue211
      value:
        integer literal UInt8InitValue211: type=DT_AFA_noObsDoneIdlIni_irv, value=0
    UInt8InitValue251
      value:
        integer literal UInt8InitValue251: type=DT_AFA_noObsSpcInjMod_irv, value=0
    UInt8InitValue35
      value:
        integer literal UInt8InitValue35: type=DT_AFA_noObsDone, value=0
    UInt8InitValue37
      value:
        integer literal UInt8InitValue37: type=DT_AFA_noRstAdpVal, value=0
    UInt8InitValue99
      value:
        integer literal UInt8InitValue99: type=DT_AFA_noObsDone, value=0
  internal behavior IB_AFAT: component=AFAT
    timing event EV_AFAT_005_TEV: mode-dependency=dependent-on-mode=[R_UCE_stWkuMainRelSt.RCD_stWkuMainRelSt.PreMainWakeUp, R_UCE_stWkuMainRelSt.RCD_stWkuMainRelSt.PostMainWakeUp, R_UCE_stWkuMainRelSt.RCD_stWkuMainRelSt.Invalid], start-on-event=RE_AFAT_005_TEV, period=0.2
    mode switch event EV_AFAT_001_MSE: start-on-event=RE_AFAT_001_MSE, activation=ENTRY, mode=R_EcuM_CurrentMode.currentMode.RUN
    mode switch event EV_AFAT_003_MSE: start-on-event=RE_AFAT_003_MSE, activation=ENTRY, mode=R_EcuM_CurrentMode.currentMode.RUN
    timing event EV_AFAT_006_TEV: mode-dependency=dependent-on-mode=[R_UCE_stWkuMainRelSt.RCD_stWkuMainRelSt.PreMainWakeUp, R_UCE_stWkuMainRelSt.RCD_stWkuMainRelSt.PostMainWakeUp, R_UCE_stWkuMainRelSt.RCD_stWkuMainRelSt.Invalid], start-on-event=RE_AFAT_006_TEV, period=0.2
    mode switch event EV_AFAT_002_MSE: start-on-event=RE_AFAT_002_MSE, activation=ENTRY, mode=R_EcuM_CurrentMode.currentMode.RUN
    timing event EV_AFAT_007_TEV: mode-dependency=dependent-on-mode=[R_UCE_stWkuMainRelSt.RCD_stWkuMainRelSt.PreMainWakeUp, R_UCE_stWkuMainRelSt.RCD_stWkuMainRelSt.PostMainWakeUp, R_UCE_stWkuMainRelSt.RCD_stWkuMainRelSt.Invalid], start-on-event=RE_AFAT_007_TEV, period=0.2
    timing event EV_AFAT_004_TEV: mode-dependency=dependent-on-mode=[R_UCE_stWkuMainRelSt.RCD_stWkuMainRelSt.PreMainWakeUp, R_UCE_stWkuMainRelSt.RCD_stWkuMainRelSt.PostMainWakeUp, R_UCE_stWkuMainRelSt.RCD_stWkuMainRelSt.Invalid], start-on-event=RE_AFAT_004_TEV, period=0.01
    34 x inter runnable variable, all with sw-calibration-access=READ-WRITE, communication-approach=EXPLICIT:
      AFA_pAirExtEstimFil_irv: type=DT_AFA_pAirExtEstimFil_irv, init-value=UInt16InitValue259
      AFA_bAdpClcRstReqHld_irv: type=DT_AFA_bAdpClcRstReqHld_irv, init-value=BooleanInitValue255
      AFA_pDsThrEstimFil_irv: type=DT_AFA_pDsThrEstimFil_irv, init-value=UInt16InitValue235
      AFA_pAirExtEstimHld_irv: type=DT_AFA_pAirExtEstimHld_irv, init-value=UInt16InitValue201
      AFA_bIdcInv_covPredInnov_irv: type=DT_AFA_bIdcInv_covPredInnov_irv, init-value=BooleanInitValue239
      AFA_pDsThrPred_facVlvOvlpFil_irv: type=DT_AFA_pDsThrPred_facVlvOvlpFil_irv, init-value=UInt16InitValue247
      AFA_pExMnfEstimFil_irv: type=DT_AFA_pExMnfEstimFil_irv, init-value=UInt16InitValue227
      AFA_facRhoFuFil_irv: type=DT_AFA_facRhoFuFil_irv, init-value=UInt8InitValue207
      AFA_noObsSpcInjMod_irv: type=DT_AFA_noObsSpcInjMod_irv, init-value=UInt8InitValue251
      AFA_nEngFil_irv: type=DT_AFA_nEngFil_irv, init-value=UInt16InitValue229
      AFA_rTotLdExCorFil_irv: type=DT_AFA_rTotLdExCorFil_irv, init-value=UInt16InitValue205
      AFA_agCkClsInVlvEstimRef1Fil_irv: type=DT_AFA_agCkClsInVlvEstimRef1Fil_irv, init-value=UInt16InitValue209
      AFA_arEffEGRVlvFil_irv: type=DT_AFA_arEffEGRVlvFil_irv, init-value=UInt16InitValue221
      AFA_tExMnfEstimFil_irv: type=DT_AFA_tExMnfEstimFil_irv, init-value=UInt16InitValue219
      AFA_agCkClsExVlvEstimRef1Fil_irv: type=DT_AFA_agCkClsExVlvEstimRef1Fil_irv, init-value=SInt16InitValue217
      AFA_rOpClsThrBolHld_irv: type=DT_AFA_rOpClsThrBolHld_irv, init-value=UInt16InitValue241
      AFA_arEffAdpEGRVlvFil_irv: type=DT_AFA_arEffAdpEGRVlvFil_irv, init-value=UInt16InitValue199
      AFA_tAirUsInVlvEstimFil_irv: type=DT_AFA_tAirUsInVlvEstimFil_irv, init-value=UInt32InitValue195
      AFA_agCkOpInVlvEstimRef1Fil_irv: type=DT_AFA_agCkOpInVlvEstimRef1Fil_irv, init-value=SInt16InitValue193
      AFA_nEngCorFil_irv: type=DT_AFA_nEngCorFil_irv, init-value=UInt16InitValue233
      AFA_agCkOpInVlvBolHld_irv: type=DT_AFA_agCkOpInVlvBolHld_irv, init-value=UInt16InitValue203
      AFA_arEffAdpThrFil_irv: type=DT_AFA_arEffAdpThrFil_irv, init-value=UInt16InitValue225
      AFA_mFuReqFil_irv: type=DT_AFA_mFuReqFil_irv, init-value=UInt32InitValue245
      AFA_rOpSIFil_irv: type=DT_AFA_rOpSIFil_irv, init-value=UInt16InitValue231
      AFA_agCkClsExVlvBolHld_irv: type=DT_AFA_agCkClsExVlvBolHld_irv, init-value=UInt16InitValue223
      AFA_noObsDoneIdlIni_irv: type=DT_AFA_noObsDoneIdlIni_irv, init-value=UInt8InitValue211
      AFA_tCoMesFil_irv: type=DT_AFA_tCoMesFil_irv, init-value=SInt16InitValue213
      AFA_pDsThrCorFil_irv: type=DT_AFA_pDsThrCorFil_irv, init-value=UInt16InitValue257
      AFA_rEthStoichFil_irv: type=DT_AFA_rEthStoichFil_irv, init-value=UInt16InitValue249
      AFA_rInMassFlowFil_irv: type=DT_AFA_rInMassFlowFil_irv, init-value=UInt16InitValue253
      AFA_pDsThrEstimErrFil_irv: type=DT_AFA_pDsThrEstimErrFil_irv, init-value=SInt16InitValue237
      AFA_rOpClsEGRVlvBolHld_irv: type=DT_AFA_rOpClsEGRVlvBolHld_irv, init-value=UInt16InitValue215
      AFA_noObsInnovNotCoh_irv: type=DT_AFA_noObsInnovNotCoh_irv, init-value=UInt8InitValue197
      AFA_facSlopEfcCorFil_irv: type=DT_AFA_facSlopEfcCorFil_irv, init-value=UInt32InitValue243
    17 x per instance memory:
      AFA_prm_facKalmMat_PIM: type=AFA_prm_facKalmMat_PIM_rt_Array_sfix16_E15_16, type-definition=rt_Array_SInt16_16_m0
      AFA_prm_rErr_PIM: type=AFA_prm_rErr_PIM_rt_Array_sfix16_E13_8, type-definition=rt_Array_SInt16_8_m0
      AFA_prm_facMes_PIM: type=AFA_prm_facMes_PIM_rt_Array_sfix16_E8_2, type-definition=rt_Array_SInt16_2_m0
      AFA_prm_covPredErrMat_PIM: type=AFA_prm_covPredErrMat_PIM_rt_Array_ufix16_E15_64, type-definition=rt_Array_UInt16_64_m0
      AFA_prm_facOutInnov_PIM: type=AFA_prm_facOutInnov_PIM_rt_Array_sfix16_E8_2, type-definition=rt_Array_SInt16_2_m0
      AFA_prm_facGainInjFil_PIM: type=AFA_prm_facGainInjFil_PIM_rt_Array_ufix32_E6_4, type-definition=rt_Array_UInt32_4_m0
      AFA_prm_covNoiseVal_PIM: type=AFA_prm_covNoiseVal_PIM_rt_Array_ufix16_E15_8, type-definition=rt_Array_UInt16_8_m0
      AFA_prm_pDifInjrFil_PIM: type=AFA_prm_pDifInjrFil_PIM_rt_Array_ufix32_En9_4, type-definition=rt_Array_UInt32_4_m0
      AFA_prm_facSenTransMat_PIM: type=AFA_prm_facSenTransMat_PIM_rt_Array_sfix32_E10_16, type-definition=rt_Array_SInt32_16_m0
      AFA_prm_covNoiseMesMat_PIM: type=AFA_prm_covNoiseMesMat_PIM_rt_Array_ufix8_E2_4, type-definition=rt_Array_UInt8_4_m0
      AFA_prm_facCorGainLnrFil_PIM: type=AFA_prm_facCorGainLnrFil_PIM_rt_Array_ufix16_E15_4, type-definition=rt_Array_UInt16_4_m0
      AFA_prm_facInterMat_PIM: type=AFA_prm_facInterMat_PIM_rt_Array_sfix16_E9_16, type-definition=rt_Array_SInt16_16_m0
      AFA_prm_bMaskSenMat_PIM: type=AFA_prm_bMaskSenMat_PIM_rt_Array_Boolean_16, type-definition=rt_Array_Boolean_16_m0
      AFA_prm_covErrEstimMat_PIM: type=AFA_prm_covErrEstimMat_PIM_rt_Array_ufix16_E15_64, type-definition=rt_Array_UInt16_64_m0
      AFA_prm_noObsDoneMat_PIM: type=AFA_prm_noObsDoneMat_PIM_rt_Array_UInt8_9, type-definition=rt_Array_UInt8_9_m0
      AFA_prm_covIvsPredInnovMat_PIM: type=AFA_prm_covIvsPredInnovMat_PIM_rt_Array_ufix16_E15_4, type-definition=rt_Array_UInt16_4_m0
      AFA_prm_facSenMat_PIM: type=AFA_prm_facSenMat_PIM_rt_Array_sfix32_E10_16, type-definition=rt_Array_SInt32_16_m0
    7 x runnable:
      RE_AFAT_002_MSE: written-variable=[AFA_rOpClsThrBolHld_irv, AFA_agCkClsExVlvBolHld_irv, AFA_rOpClsEGRVlvBolHld_irv, AFA_agCkOpInVlvBolHld_irv, AFA_pAirExtEstimHld_irv, AFA_noObsDoneIdlIni_irv, AFA_noObsSpcInjMod_irv, AFA_bAdpClcRstReqHld_irv, AFA_noObsInnovNotCoh_irv]
        33 x data receive point:
          dr_AFA_bAcvSpcInjMod: data-element=R_AFA_bAcvSpcInjMod.AFA_bAcvSpcInjMod
          dr_AFA_bClsEGRRef: data-element=R_AFA_bClsEGRRef.AFA_bClsEGRRef
          dr_UsThrM_pAirExtEstim: data-element=R_UsThrM_pAirExtEstim.UsThrM_pAirExtEstim
          dr_AFA_rCor_arEffEGRVlv: data-element=R_AFA_rCor_arEffEGRVlv.AFA_rCor_arEffEGRVlv
          dr_AFA_facArEffThrOfs3: data-element=R_AFA_facArEffThrOfs3.AFA_facArEffThrOfs3
          dr_AFA_bFitPresAirExt: data-element=R_AFA_bFitPresAirExt.AFA_bFitPresAirExt
          dr_EGRVlv_rOpClsEGRVlvBol: data-element=R_EGRVlv_rOpClsEGRVlvBol.EGRVlv_rOpClsEGRVlvBol
          dr_AFAMgt_bAdpOfsRstReq: data-element=R_AFAMgt_bAdpOfsRstReq.AFAMgt_bAdpOfsRstReq
          dr_AFA_noAdpClcRst: data-element=R_AFA_noAdpClcRst.AFA_noAdpClcRst
          dr_VlvAct_prm_agCkOpInVlvBol: data-element=R_VlvAct_prm_agCkOpInVlvBol.VlvAct_prm_agCkOpInVlvBol
          dr_AFA_prm_covErrEstim: data-element=R_AFA_prm_covErrEstim.AFA_prm_covErrEstim
          dr_AFA_agCkOpInVlvOfs: data-element=R_AFA_agCkOpInVlvOfs.AFA_agCkOpInVlvOfs
          dr_AFA_facSlopInjGain: data-element=R_AFA_facSlopInjGain.AFA_facSlopInjGain
          dr_AFA_agCkClsExVlvOfs: data-element=R_AFA_agCkClsExVlvOfs.AFA_agCkClsExVlvOfs
          dr_AFA_facArEffThrOfs2: data-element=R_AFA_facArEffThrOfs2.AFA_facArEffThrOfs2
          dr_AFA_bFitZeroPosnThr: data-element=R_AFA_bFitZeroPosnThr.AFA_bFitZeroPosnThr
          dr_AFA_noAdpEfcAst: data-element=R_AFA_noAdpEfcAst.AFA_noAdpEfcAst
          dr_AFAMgt_bAdpClcRstReq: data-element=R_AFAMgt_bAdpClcRstReq.AFAMgt_bAdpClcRstReq
          dr_AFA_tiDlyLstObs: data-element=R_AFA_tiDlyLstObs.AFA_tiDlyLstObs
          dr_AFA_noObsDone: data-element=R_AFA_noObsDone.AFA_noObsDone
          dr_AFA_noAdpEfc: data-element=R_AFA_noAdpEfc.AFA_noAdpEfc
          dr_AFA_bFitClsExVlvBol: data-element=R_AFA_bFitClsExVlvBol.AFA_bFitClsExVlvBol
          dr_AFA_tiOffInj: data-element=R_AFA_tiOffInj.AFA_tiOffInj
          dr_AFA_arEffThrOfs: data-element=R_AFA_arEffThrOfs.AFA_arEffThrOfs
          dr_AFA_bFitOpInVlvBol: data-element=R_AFA_bFitOpInVlvBol.AFA_bFitOpInVlvBol
          dr_ThrLrn_rOpClsThrBol: data-element=R_ThrLrn_rOpClsThrBol.ThrLrn_rOpClsThrBol
          dr_VlvAct_prm_agCkClsExVlvBol: data-element=R_VlvAct_prm_agCkClsExVlvBol.VlvAct_prm_agCkClsExVlvBol
          dr_AFA_facIvsInjGain: data-element=R_AFA_facIvsInjGain.AFA_facIvsInjGain
          dr_AFA_bEngStopAuth: data-element=R_AFA_bEngStopAuth.AFA_bEngStopAuth
          dr_AFA_facArEffThrOfs1: data-element=R_AFA_facArEffThrOfs1.AFA_facArEffThrOfs1
          dr_AFA_noRstAdpVal: data-element=R_AFA_noRstAdpVal.AFA_noRstAdpVal
          dr_AFA_arEffEGRVlvOfs: data-element=R_AFA_arEffEGRVlvOfs.AFA_arEffEGRVlvOfs
          dr_AFA_bAuthClsCanPurg: data-element=R_AFA_bAuthClsCanPurg.AFA_bAuthClsCanPurg
        26 x data send point:
          ds_AFA_bClsEGRRef: data-element=P_AFA_bClsEGRRef.AFA_bClsEGRRef
          ds_AFA_bFitZeroPosnThr: data-element=P_AFA_bFitZeroPosnThr.AFA_bFitZeroPosnThr
          ds_AFA_rCor_arEffEGRVlv: data-element=P_AFA_rCor_arEffEGRVlv.AFA_rCor_arEffEGRVlv
          ds_AFA_noAdpEfc: data-element=P_AFA_noAdpEfc.AFA_noAdpEfc
          ds_AFA_bFitPresAirExt: data-element=P_AFA_bFitPresAirExt.AFA_bFitPresAirExt
          ds_AFA_tiOffInj: data-element=P_AFA_tiOffInj.AFA_tiOffInj
          ds_AFA_bAcvSpcInjMod: data-element=P_AFA_bAcvSpcInjMod.AFA_bAcvSpcInjMod
          ds_AFA_facArEffThrOfs2: data-element=P_AFA_facArEffThrOfs2.AFA_facArEffThrOfs2
          ds_AFA_bEngStopAuth: data-element=P_AFA_bEngStopAuth.AFA_bEngStopAuth
          ds_AFA_bFitClsExVlvBol: data-element=P_AFA_bFitClsExVlvBol.AFA_bFitClsExVlvBol
          ds_AFA_facIvsInjGain: data-element=P_AFA_facIvsInjGain.AFA_facIvsInjGain
          ds_AFA_noRstAdpVal: data-element=P_AFA_noRstAdpVal.AFA_noRstAdpVal
          ds_AFA_prm_covErrEstim: data-element=P_AFA_prm_covErrEstim.AFA_prm_covErrEstim
          ds_AFA_noAdpEfcAst: data-element=P_AFA_noAdpEfcAst.AFA_noAdpEfcAst
          ds_AFA_noObsDone: data-element=P_AFA_noObsDone.AFA_noObsDone
          ds_AFA_bFitOpInVlvBol: data-element=P_AFA_bFitOpInVlvBol.AFA_bFitOpInVlvBol
          ds_AFA_noAdpClcRst: data-element=P_AFA_noAdpClcRst.AFA_noAdpClcRst
          ds_AFA_arEffEGRVlvOfs: data-element=P_AFA_arEffEGRVlvOfs.AFA_arEffEGRVlvOfs
          ds_AFA_tiDlyLstObs: data-element=P_AFA_tiDlyLstObs.AFA_tiDlyLstObs
          ds_AFA_agCkClsExVlvOfs: data-element=P_AFA_agCkClsExVlvOfs.AFA_agCkClsExVlvOfs
          ds_AFA_facSlopInjGain: data-element=P_AFA_facSlopInjGain.AFA_facSlopInjGain
          ds_AFA_arEffThrOfs: data-element=P_AFA_arEffThrOfs.AFA_arEffThrOfs
          ds_AFA_agCkOpInVlvOfs: data-element=P_AFA_agCkOpInVlvOfs.AFA_agCkOpInVlvOfs
          ds_AFA_facArEffThrOfs1: data-element=P_AFA_facArEffThrOfs1.AFA_facArEffThrOfs1
          ds_AFA_facArEffThrOfs3: data-element=P_AFA_facArEffThrOfs3.AFA_facArEffThrOfs3
          ds_AFA_bAuthClsCanPurg: data-element=P_AFA_bAuthClsCanPurg.AFA_bAuthClsCanPurg
      RE_AFAT_005_TEV: read-variable=[AFA_arEffAdpEGRVlvFil_irv, AFA_noObsSpcInjMod_irv, AFA_noObsDoneIdlIni_irv, AFA_rInMassFlowFil_irv, AFA_arEffEGRVlvFil_irv, AFA_facRhoFuFil_irv, AFA_arEffAdpThrFil_irv, AFA_nEngCorFil_irv, AFA_agCkClsInVlvEstimRef1Fil_irv, AFA_facSlopEfcCorFil_irv, AFA_tExMnfEstimFil_irv, AFA_rEthStoichFil_irv, AFA_pExMnfEstimFil_irv, AFA_noObsInnovNotCoh_irv, AFA_agCkClsExVlvEstimRef1Fil_irv, AFA_agCkOpInVlvEstimRef1Fil_irv, AFA_rTotLdExCorFil_irv, AFA_nEngFil_irv, AFA_pDsThrEstimErrFil_irv, AFA_pDsThrPred_facVlvOvlpFil_irv, AFA_tAirUsInVlvEstimFil_irv, AFA_tCoMesFil_irv, AFA_pDsThrCorFil_irv, AFA_pAirExtEstimFil_irv, AFA_pDsThrEstimFil_irv, AFA_bAdpClcRstReqHld_irv, AFA_rOpSIFil_irv, AFA_mFuReqFil_irv, AFA_bIdcInv_covPredInnov_irv], written-variable=[AFA_noObsSpcInjMod_irv, AFA_noObsDoneIdlIni_irv, AFA_rOpClsEGRVlvBolHld_irv, AFA_noObsInnovNotCoh_irv, AFA_agCkOpInVlvBolHld_irv, AFA_rOpClsThrBolHld_irv, AFA_pAirExtEstimHld_irv, AFA_agCkClsExVlvBolHld_irv, AFA_bAdpClcRstReqHld_irv, AFA_bIdcInv_covPredInnov_irv]
        49 x data receive point:
          dr_AFA_bInnovTestCohDone: data-element=R_AFA_bInnovTestCohDone.AFA_bInnovTestCohDone
          dr_IdlSys_bAcvIdlCtl: data-element=R_IdlSys_bAcvIdlCtl.IdlSys_bAcvIdlCtl
          dr_ThrLrn_rOpSI: data-element=R_ThrLrn_rOpSI.ThrLrn_rOpSI
          dr_AFA_arEffEGRVlvOfs: data-element=R_AFA_arEffEGRVlvOfs.AFA_arEffEGRVlvOfs
          dr_AFA_bFitClsExVlvBol: data-element=R_AFA_bFitClsExVlvBol.AFA_bFitClsExVlvBol
          dr_AFA_agCkClsExVlvOfs: data-element=R_AFA_agCkClsExVlvOfs.AFA_agCkClsExVlvOfs
          dr_AFA_bFitZeroPosnThr: data-element=R_AFA_bFitZeroPosnThr.AFA_bFitZeroPosnThr
          dr_AFA_facArEffThrOfs2: data-element=R_AFA_facArEffThrOfs2.AFA_facArEffThrOfs2
          dr_EOM_bSpcInjMod: data-element=R_EOM_bSpcInjMod.EOM_bSpcInjMod
          dr_AFAMgt_bAdpEfcReq: data-element=R_AFAMgt_bAdpEfcReq.AFAMgt_bAdpEfcReq
          dr_AFAMgt_bIdcInjrMdlCnd: data-element=R_AFAMgt_bIdcInjrMdlCnd.AFAMgt_bIdcInjrMdlCnd
          dr_AFA_facSlopInjGain: data-element=R_AFA_facSlopInjGain.AFA_facSlopInjGain
          dr_VlvAct_prm_agCkOpInVlvBol: data-element=R_VlvAct_prm_agCkOpInVlvBol.VlvAct_prm_agCkOpInVlvBol
          dr_VlvAct_prm_agCkClsExVlvBol: data-element=R_VlvAct_prm_agCkClsExVlvBol.VlvAct_prm_agCkClsExVlvBol
          dr_AFA_noObsDone: data-element=R_AFA_noObsDone.AFA_noObsDone
          dr_AFA_facIvsInjGain: data-element=R_AFA_facIvsInjGain.AFA_facIvsInjGain
          dr_InjrSys_prm_tiInj: data-element=R_InjrSys_prm_tiInj.InjrSys_prm_tiInj
          dr_AFA_bIdcCohLstObs: data-element=R_AFA_bIdcCohLstObs.AFA_bIdcCohLstObs
          dr_InjSys_noTDCDlyLsclFilMod: data-element=R_InjSys_noTDCDlyLsclFilMod.InjSys_noTDCDlyLsclFilMod
          dr_Ext_nEng: data-element=R_Ext_nEng.Ext_nEng
          dr_AFA_rTotLdCorLstObs: data-element=R_AFA_rTotLdCorLstObs.AFA_rTotLdCorLstObs
          dr_AFA_arEffThrOfs: data-element=R_AFA_arEffThrOfs.AFA_arEffThrOfs
          dr_EGRVlv_rOpClsEGRVlvBol: data-element=R_EGRVlv_rOpClsEGRVlvBol.EGRVlv_rOpClsEGRVlvBol
          dr_AFAMgt_bInhAFA: data-element=R_AFAMgt_bInhAFA.AFAMgt_bInhAFA
          dr_AFA_bAcvSpcInjMod: data-element=R_AFA_bAcvSpcInjMod.AFA_bAcvSpcInjMod
          dr_AFA_bFitPresAirExt: data-element=R_AFA_bFitPresAirExt.AFA_bFitPresAirExt
          dr_AFA_noAdpEfc: data-element=R_AFA_noAdpEfc.AFA_noAdpEfc
          dr_AFA_rCor_arEffEGRVlv: data-element=R_AFA_rCor_arEffEGRVlv.AFA_rCor_arEffEGRVlv
          dr_AFA_prm_covErrEstim: data-element=R_AFA_prm_covErrEstim.AFA_prm_covErrEstim
          dr_ThrLrn_rOpClsThrBol: data-element=R_ThrLrn_rOpClsThrBol.ThrLrn_rOpClsThrBol
          dr_AFAMgt_bIdcTmpObsCnd: data-element=R_AFAMgt_bIdcTmpObsCnd.AFAMgt_bIdcTmpObsCnd
          dr_AFA_noAdpEfcAst: data-element=R_AFA_noAdpEfcAst.AFA_noAdpEfcAst
          dr_AFA_tiOffInj: data-element=R_AFA_tiOffInj.AFA_tiOffInj
          dr_AFA_bClsEGRRef: data-element=R_AFA_bClsEGRRef.AFA_bClsEGRRef
          dr_AFA_bFitOpInVlvBol: data-element=R_AFA_bFitOpInVlvBol.AFA_bFitOpInVlvBol
          dr_AFA_bAuthClsCanPurg: data-element=R_AFA_bAuthClsCanPurg.AFA_bAuthClsCanPurg
          dr_AFA_facArEffThrOfs3: data-element=R_AFA_facArEffThrOfs3.AFA_facArEffThrOfs3
          dr_AFA_noAdpClcRst: data-element=R_AFA_noAdpClcRst.AFA_noAdpClcRst
          dr_AFA_rAirPresFil: data-element=R_AFA_rAirPresFil.AFA_rAirPresFil
          dr_AFAMgt_bAdpObsReq: data-element=R_AFAMgt_bAdpObsReq.AFAMgt_bAdpObsReq
          dr_AFA_rAirLdCorFil: data-element=R_AFA_rAirLdCorFil.AFA_rAirLdCorFil
          dr_AFAMgt_bAdpClcRstReq: data-element=R_AFAMgt_bAdpClcRstReq.AFAMgt_bAdpClcRstReq
          dr_AFA_tiDlyLstObs: data-element=R_AFA_tiDlyLstObs.AFA_tiDlyLstObs
          dr_InjSys_lamFbFil: data-element=R_InjSys_lamFbFil.InjSys_lamFbFil
          dr_UsThrM_pAirExtEstim: data-element=R_UsThrM_pAirExtEstim.UsThrM_pAirExtEstim
          dr_EngM_rTotLdExCor: data-element=R_EngM_rTotLdExCor.EngM_rTotLdExCor
          dr_AFA_nEngLstObs: data-element=R_AFA_nEngLstObs.AFA_nEngLstObs
          dr_AFA_agCkOpInVlvOfs: data-element=R_AFA_agCkOpInVlvOfs.AFA_agCkOpInVlvOfs
          dr_AFA_facArEffThrOfs1: data-element=R_AFA_facArEffThrOfs1.AFA_facArEffThrOfs1
        29 x data send point:
          ds_AFA_facArEffThrOfs1: data-element=P_AFA_facArEffThrOfs1.AFA_facArEffThrOfs1
          ds_AFA_noAdpClcRst: data-element=P_AFA_noAdpClcRst.AFA_noAdpClcRst
          ds_AFA_rCor_arEffEGRVlv: data-element=P_AFA_rCor_arEffEGRVlv.AFA_rCor_arEffEGRVlv
          ds_AFA_agCkOpInVlvOfs: data-element=P_AFA_agCkOpInVlvOfs.AFA_agCkOpInVlvOfs
          ds_AFA_bAcvSpcInjMod: data-element=P_AFA_bAcvSpcInjMod.AFA_bAcvSpcInjMod
          ds_AFA_tiDlyLstObs: data-element=P_AFA_tiDlyLstObs.AFA_tiDlyLstObs
          ds_AFA_noAdpEfcAst: data-element=P_AFA_noAdpEfcAst.AFA_noAdpEfcAst
          ds_AFA_bFitZeroPosnThr: data-element=P_AFA_bFitZeroPosnThr.AFA_bFitZeroPosnThr
          ds_AFA_bIdcCohLstObs: data-element=P_AFA_bIdcCohLstObs.AFA_bIdcCohLstObs
          ds_AFA_bFitOpInVlvBol: data-element=P_AFA_bFitOpInVlvBol.AFA_bFitOpInVlvBol
          ds_AFA_agCkClsExVlvOfs: data-element=P_AFA_agCkClsExVlvOfs.AFA_agCkClsExVlvOfs
          ds_AFA_prm_covErrEstim: data-element=P_AFA_prm_covErrEstim.AFA_prm_covErrEstim
          ds_AFA_facIvsInjGain: data-element=P_AFA_facIvsInjGain.AFA_facIvsInjGain
          ds_AFA_bInnovTestCohDone: data-element=P_AFA_bInnovTestCohDone.AFA_bInnovTestCohDone
          ds_AFA_bClsEGRRef: data-element=P_AFA_bClsEGRRef.AFA_bClsEGRRef
          ds_AFA_bAuthClsCanPurg: data-element=P_AFA_bAuthClsCanPurg.AFA_bAuthClsCanPurg
          ds_AFA_tiOffInj: data-element=P_AFA_tiOffInj.AFA_tiOffInj
          ds_AFA_noAdpEfc: data-element=P_AFA_noAdpEfc.AFA_noAdpEfc
          ds_AFA_rTotLdCorLstObs: data-element=P_AFA_rTotLdCorLstObs.AFA_rTotLdCorLstObs
          ds_AFA_facSlopInjGain: data-element=P_AFA_facSlopInjGain.AFA_facSlopInjGain
          ds_AFA_arEffThrOfs: data-element=P_AFA_arEffThrOfs.AFA_arEffThrOfs
          ds_AFA_bFitClsExVlvBol: data-element=P_AFA_bFitClsExVlvBol.AFA_bFitClsExVlvBol
          ds_AFA_facArEffThrOfs3: data-element=P_AFA_facArEffThrOfs3.AFA_facArEffThrOfs3
          ds_AFA_bEngStopAuth: data-element=P_AFA_bEngStopAuth.AFA_bEngStopAuth
          ds_AFA_bFitPresAirExt: data-element=P_AFA_bFitPresAirExt.AFA_bFitPresAirExt
          ds_AFA_arEffEGRVlvOfs: data-element=P_AFA_arEffEGRVlvOfs.AFA_arEffEGRVlvOfs
          ds_AFA_facArEffThrOfs2: data-element=P_AFA_facArEffThrOfs2.AFA_facArEffThrOfs2
          ds_AFA_noObsDone: data-element=P_AFA_noObsDone.AFA_noObsDone
          ds_AFA_nEngLstObs: data-element=P_AFA_nEngLstObs.AFA_nEngLstObs
        10 x sync call:
          ssp_AFAT_AFA_AdpClsExOfsLim: operation=R_AFAT_AFA_AdpClsExOfsLim.SetEventStatus
          ssp_AFAT_AFA_AdpArEffThrOfs3Lim: operation=R_AFAT_AFA_AdpArEffThrOfs3Lim.SetEventStatus
          ssp_AFAT_AFA_AdpSlopInjConLim: operation=R_AFAT_AFA_AdpSlopInjConLim.SetEventStatus
          ssp_AFAT_AFA_AdpInjOfsLim: operation=R_AFAT_AFA_AdpInjOfsLim.SetEventStatus
          ssp_AFAT_AFA_AdpArEffThrOfsLim: operation=R_AFAT_AFA_AdpArEffThrOfsLim.SetEventStatus
          ssp_AFAT_AFA_AdpArEffEGRVlvLim: operation=R_AFAT_AFA_AdpArEffEGRVlvLim.SetEventStatus
          ssp_AFAT_AFA_AdpOpInOfsLim: operation=R_AFAT_AFA_AdpOpInOfsLim.SetEventStatus
          ssp_AFAT_AFA_AdpIvsInjConLim: operation=R_AFAT_AFA_AdpIvsInjConLim.SetEventStatus
          ssp_AFAT_AFA_AdpArEffThrOfs2Lim: operation=R_AFAT_AFA_AdpArEffThrOfs2Lim.SetEventStatus
          ssp_AFAT_AFA_AdpArEffThrOfs1Lim: operation=R_AFAT_AFA_AdpArEffThrOfs1Lim.SetEventStatus
      RE_AFAT_006_TEV
        data receive point dr_AFA_tiDlyLstObs: data-element=R_AFA_tiDlyLstObs.AFA_tiDlyLstObs
        data send point ds_AFA_tiDlyLstObs: data-element=P_AFA_tiDlyLstObs.AFA_tiDlyLstObs
      RE_AFAT_003_MSE: written-variable=[AFA_facRhoFuFil_irv, AFA_tAirUsInVlvEstimFil_irv, AFA_pDsThrEstimFil_irv, AFA_pExMnfEstimFil_irv, AFA_pDsThrCorFil_irv, AFA_rInMassFlowFil_irv, AFA_rEthStoichFil_irv, AFA_pAirExtEstimFil_irv, AFA_arEffAdpThrFil_irv, AFA_mFuReqFil_irv, AFA_agCkClsExVlvEstimRef1Fil_irv, AFA_rTotLdExCorFil_irv, AFA_arEffEGRVlvFil_irv, AFA_tExMnfEstimFil_irv, AFA_pDsThrEstimErrFil_irv, AFA_arEffAdpEGRVlvFil_irv, AFA_pDsThrPred_facVlvOvlpFil_irv, AFA_tCoMesFil_irv, AFA_agCkClsInVlvEstimRef1Fil_irv, AFA_nEngFil_irv, AFA_facSlopEfcCorFil_irv, AFA_agCkOpInVlvEstimRef1Fil_irv, AFA_rOpSIFil_irv, AFA_nEngCorFil_irv]
        30 x data receive point:
          dr_EngM_agCkClsExVlvEstimRef1: data-element=R_EngM_agCkClsExVlvEstimRef1.EngM_agCkClsExVlvEstimRef1
          dr_UsThrM_pUsThrCor: data-element=R_UsThrM_pUsThrCor.UsThrM_pUsThrCor
          dr_ExM_tExMnfEstim: data-element=R_ExM_tExMnfEstim.ExM_tExMnfEstim
          dr_AfuA_rEthStoich: data-element=R_AfuA_rEthStoich.AfuA_rEthStoich
          dr_InM_pDsThrEstimErr: data-element=R_InM_pDsThrEstimErr.InM_pDsThrEstimErr
          dr_InjSys_mFuReq: data-element=R_InjSys_mFuReq.InjSys_mFuReq
          dr_InM_arEffAdpEGRVlv: data-element=R_InM_arEffAdpEGRVlv.InM_arEffAdpEGRVlv
          dr_Ext_nEng: data-element=R_Ext_nEng.Ext_nEng
          dr_EngM_agCkClsInVlvEstimRef1: data-element=R_EngM_agCkClsInVlvEstimRef1.EngM_agCkClsInVlvEstimRef1
          dr_InjrM_prm_facCorGainLnr: data-element=R_InjrM_prm_facCorGainLnr.InjrM_prm_facCorGainLnr
          dr_EngM_rTotLdExCor: data-element=R_EngM_rTotLdExCor.EngM_rTotLdExCor
          dr_InM_pDsThrEstim: data-element=R_InM_pDsThrEstim.InM_pDsThrEstim
          dr_Ext_facRhoFu: data-element=R_Ext_facRhoFu.Ext_facRhoFu
          dr_InThM_nEngCor: data-element=R_InThM_nEngCor.InThM_nEngCor
          dr_EngM_facSlopEfcCor: data-element=R_EngM_facSlopEfcCor.EngM_facSlopEfcCor
          dr_InThM_tAirUsInVlvEstim: data-element=R_InThM_tAirUsInVlvEstim.InThM_tAirUsInVlvEstim
          dr_EngM_rAirLdCor: data-element=R_EngM_rAirLdCor.EngM_rAirLdCor
          dr_InjrM_prm_pDifInjr: data-element=R_InjrM_prm_pDifInjr.InjrM_prm_pDifInjr
          dr_InM_pDsThrCor: data-element=R_InM_pDsThrCor.InM_pDsThrCor
          dr_InjrM_prm_facGainInj: data-element=R_InjrM_prm_facGainInj.InjrM_prm_facGainInj
          dr_EngM_agCkOpInVlvEstimRef1: data-element=R_EngM_agCkOpInVlvEstimRef1.EngM_agCkOpInVlvEstimRef1
          dr_ExM_pExMnfEstim_facVlvOvlp: data-element=R_ExM_pExMnfEstim_facVlvOvlp.ExM_pExMnfEstim_facVlvOvlp
          dr_InM_arEffAdpThr: data-element=R_InM_arEffAdpThr.InM_arEffAdpThr
          dr_InM_pDsThrPred: data-element=R_InM_pDsThrPred.InM_pDsThrPred
          dr_UsThrM_pAirExt: data-element=R_UsThrM_pAirExt.UsThrM_pAirExt
          dr_ThrLrn_rOpSI: data-element=R_ThrLrn_rOpSI.ThrLrn_rOpSI
          dr_InM_arEffEGRVlv: data-element=R_InM_arEffEGRVlv.InM_arEffEGRVlv
          dr_Ext_tCoMes: data-element=R_Ext_tCoMes.Ext_tCoMes
          dr_InM_rAirPres: data-element=R_InM_rAirPres.InM_rAirPres
          dr_InM_pDsThrPred_facVlvOvlp: data-element=R_InM_pDsThrPred_facVlvOvlp.InM_pDsThrPred_facVlvOvlp
        4 x data send point:
          ds_AFA_rAirLdCorFil: data-element=P_AFA_rAirLdCorFil.AFA_rAirLdCorFil
          ds_AFA_pDsThrPredFil: data-element=P_AFA_pDsThrPredFil.AFA_pDsThrPredFil
          ds_AFA_pUsThrCorFil: data-element=P_AFA_pUsThrCorFil.AFA_pUsThrCorFil
          ds_AFA_rAirPresFil: data-element=P_AFA_rAirPresFil.AFA_rAirPresFil
      RE_AFAT_007_TEV: read-variable=[AFA_rOpClsThrBolHld_irv, AFA_pAirExtEstimHld_irv, AFA_agCkClsExVlvBolHld_irv, AFA_rOpClsEGRVlvBolHld_irv, AFA_agCkOpInVlvBolHld_irv], written-variable=[AFA_rOpClsThrBolHld_irv, AFA_pAirExtEstimHld_irv, AFA_agCkClsExVlvBolHld_irv, AFA_rOpClsEGRVlvBolHld_irv, AFA_agCkOpInVlvBolHld_irv]
        10 x data receive point:
          dr_VlvAct_prm_agCkClsExVlvBol: data-element=R_VlvAct_prm_agCkClsExVlvBol.VlvAct_prm_agCkClsExVlvBol
          dr_AFA_bFitPresAirExt: data-element=R_AFA_bFitPresAirExt.AFA_bFitPresAirExt
          dr_ThrLrn_rOpClsThrBol: data-element=R_ThrLrn_rOpClsThrBol.ThrLrn_rOpClsThrBol
          dr_VlvAct_prm_agCkOpInVlvBol: data-element=R_VlvAct_prm_agCkOpInVlvBol.VlvAct_prm_agCkOpInVlvBol
          dr_AFA_bFitZeroPosnThr: data-element=R_AFA_bFitZeroPosnThr.AFA_bFitZeroPosnThr
          dr_AFA_bFitOpInVlvBol: data-element=R_AFA_bFitOpInVlvBol.AFA_bFitOpInVlvBol
          dr_EGRVlv_rOpClsEGRVlvBol: data-element=R_EGRVlv_rOpClsEGRVlvBol.EGRVlv_rOpClsEGRVlvBol
          dr_AFA_bFitClsExVlvBol: data-element=R_AFA_bFitClsExVlvBol.AFA_bFitClsExVlvBol
          dr_AFA_bClsEGRRef: data-element=R_AFA_bClsEGRRef.AFA_bClsEGRRef
          dr_UsThrM_pAirExtEstim: data-element=R_UsThrM_pAirExtEstim.UsThrM_pAirExtEstim
        5 x data send point:
          ds_AFA_bFitOpInVlvBol: data-element=P_AFA_bFitOpInVlvBol.AFA_bFitOpInVlvBol
          ds_AFA_bFitPresAirExt: data-element=P_AFA_bFitPresAirExt.AFA_bFitPresAirExt
          ds_AFA_bFitZeroPosnThr: data-element=P_AFA_bFitZeroPosnThr.AFA_bFitZeroPosnThr
          ds_AFA_bFitClsExVlvBol: data-element=P_AFA_bFitClsExVlvBol.AFA_bFitClsExVlvBol
          ds_AFA_bClsEGRRef: data-element=P_AFA_bClsEGRRef.AFA_bClsEGRRef
      RE_AFAT_004_TEV: written-variable=[AFA_facRhoFuFil_irv, AFA_pDsThrEstimFil_irv, AFA_rTotLdExCorFil_irv, AFA_agCkClsInVlvEstimRef1Fil_irv, AFA_tExMnfEstimFil_irv, AFA_tAirUsInVlvEstimFil_irv, AFA_arEffEGRVlvFil_irv, AFA_nEngCorFil_irv, AFA_mFuReqFil_irv, AFA_agCkOpInVlvEstimRef1Fil_irv, AFA_tCoMesFil_irv, AFA_pExMnfEstimFil_irv, AFA_arEffAdpThrFil_irv, AFA_nEngFil_irv, AFA_facSlopEfcCorFil_irv, AFA_rOpSIFil_irv, AFA_arEffAdpEGRVlvFil_irv, AFA_agCkClsExVlvEstimRef1Fil_irv, AFA_pDsThrCorFil_irv, AFA_pDsThrPred_facVlvOvlpFil_irv, AFA_rInMassFlowFil_irv, AFA_pDsThrEstimErrFil_irv, AFA_rEthStoichFil_irv, AFA_pAirExtEstimFil_irv]
        32 x data receive point:
          dr_EngM_rTotLdExCor: data-element=R_EngM_rTotLdExCor.EngM_rTotLdExCor
          dr_InM_pDsThrEstim: data-element=R_InM_pDsThrEstim.InM_pDsThrEstim
          dr_InM_pDsThrPred: data-element=R_InM_pDsThrPred.InM_pDsThrPred
          dr_InM_arEffAdpThr: data-element=R_InM_arEffAdpThr.InM_arEffAdpThr
          dr_Ext_facRhoFu: data-element=R_Ext_facRhoFu.Ext_facRhoFu
          dr_EngM_rAirLdCor: data-element=R_EngM_rAirLdCor.EngM_rAirLdCor
          dr_UsThrM_pUsThrCor: data-element=R_UsThrM_pUsThrCor.UsThrM_pUsThrCor
          dr_InM_pDsThrPred_facVlvOvlp: data-element=R_InM_pDsThrPred_facVlvOvlp.InM_pDsThrPred_facVlvOvlp
          dr_InjSys_mFuReq: data-element=R_InjSys_mFuReq.InjSys_mFuReq
          dr_ExM_tExMnfEstim: data-element=R_ExM_tExMnfEstim.ExM_tExMnfEstim
          dr_InM_rAirPres: data-element=R_InM_rAirPres.InM_rAirPres
          dr_InM_pDsThrEstimErr: data-element=R_InM_pDsThrEstimErr.InM_pDsThrEstimErr
          dr_InjrM_prm_facGainInj: data-element=R_InjrM_prm_facGainInj.InjrM_prm_facGainInj
          dr_UsThrM_pAirExt: data-element=R_UsThrM_pAirExt.UsThrM_pAirExt
          dr_InThM_tAirUsInVlvEstim: data-element=R_InThM_tAirUsInVlvEstim.InThM_tAirUsInVlvEstim
          dr_InM_pDsThrCor: data-element=R_InM_pDsThrCor.InM_pDsThrCor
          dr_InM_arEffEGRVlv: data-element=R_InM_arEffEGRVlv.InM_arEffEGRVlv
          dr_EngM_agCkOpInVlvEstimRef1: data-element=R_EngM_agCkOpInVlvEstimRef1.EngM_agCkOpInVlvEstimRef1
          dr_InM_mfAirThrEstim: data-element=R_InM_mfAirThrEstim.InM_mfAirThrEstim
          dr_InjrM_prm_pDifInjr: data-element=R_InjrM_prm_pDifInjr.InjrM_prm_pDifInjr
          dr_Ext_tCoMes: data-element=R_Ext_tCoMes.Ext_tCoMes
          dr_InjrM_prm_facCorGainLnr: data-element=R_InjrM_prm_facCorGainLnr.InjrM_prm_facCorGainLnr
          dr_Ext_nEng: data-element=R_Ext_nEng.Ext_nEng
          dr_InThM_nEngCor: data-element=R_InThM_nEngCor.InThM_nEngCor
          dr_InM_mfEGREstimEGRVlv: data-element=R_InM_mfEGREstimEGRVlv.InM_mfEGREstimEGRVlv
          dr_EngM_facSlopEfcCor: data-element=R_EngM_facSlopEfcCor.EngM_facSlopEfcCor
          dr_InM_arEffAdpEGRVlv: data-element=R_InM_arEffAdpEGRVlv.InM_arEffAdpEGRVlv
          dr_EngM_agCkClsInVlvEstimRef1: data-element=R_EngM_agCkClsInVlvEstimRef1.EngM_agCkClsInVlvEstimRef1
          dr_EngM_agCkClsExVlvEstimRef1: data-element=R_EngM_agCkClsExVlvEstimRef1.EngM_agCkClsExVlvEstimRef1
          dr_ExM_pExMnfEstim_facVlvOvlp: data-element=R_ExM_pExMnfEstim_facVlvOvlp.ExM_pExMnfEstim_facVlvOvlp
          dr_AfuA_rEthStoich: data-element=R_AfuA_rEthStoich.AfuA_rEthStoich
          dr_ThrLrn_rOpSI: data-element=R_ThrLrn_rOpSI.ThrLrn_rOpSI
        4 x data send point:
          ds_AFA_rAirLdCorFil: data-element=P_AFA_rAirLdCorFil.AFA_rAirLdCorFil
          ds_AFA_pUsThrCorFil: data-element=P_AFA_pUsThrCorFil.AFA_pUsThrCorFil
          ds_AFA_rAirPresFil: data-element=P_AFA_rAirPresFil.AFA_rAirPresFil
          ds_AFA_pDsThrPredFil: data-element=P_AFA_pDsThrPredFil.AFA_pDsThrPredFil
      RE_AFAT_001_MSE: written-variable=[AFA_tAirUsInVlvEstimFil_irv, AFA_pAirExtEstimHld_irv, AFA_pExMnfEstimFil_irv, AFA_rOpClsEGRVlvBolHld_irv, AFA_pDsThrEstimErrFil_irv, AFA_noObsDoneIdlIni_irv, AFA_rTotLdExCorFil_irv, AFA_rOpClsThrBolHld_irv, AFA_facSlopEfcCorFil_irv, AFA_pDsThrPred_facVlvOvlpFil_irv, AFA_bIdcInv_covPredInnov_irv, AFA_agCkClsExVlvEstimRef1Fil_irv, AFA_agCkOpInVlvBolHld_irv, AFA_agCkOpInVlvEstimRef1Fil_irv, AFA_rOpSIFil_irv, AFA_agCkClsExVlvBolHld_irv, AFA_arEffAdpThrFil_irv, AFA_bAdpClcRstReqHld_irv, AFA_tExMnfEstimFil_irv, AFA_arEffEGRVlvFil_irv, AFA_nEngCorFil_irv, AFA_pDsThrCorFil_irv, AFA_agCkClsInVlvEstimRef1Fil_irv, AFA_nEngFil_irv, AFA_arEffAdpEGRVlvFil_irv, AFA_rInMassFlowFil_irv, AFA_pDsThrEstimFil_irv, AFA_pAirExtEstimFil_irv, AFA_tCoMesFil_irv, AFA_mFuReqFil_irv, AFA_noObsSpcInjMod_irv]
        34 x data send point:
          ds_AFA_pDsThrPredFil: data-element=P_AFA_pDsThrPredFil.AFA_pDsThrPredFil
          ds_AFA_bFitClsExVlvBol: data-element=P_AFA_bFitClsExVlvBol.AFA_bFitClsExVlvBol
          ds_AFA_pUsThrCorFil: data-element=P_AFA_pUsThrCorFil.AFA_pUsThrCorFil
          ds_AFA_bFitPresAirExt: data-element=P_AFA_bFitPresAirExt.AFA_bFitPresAirExt
          ds_AFA_bClsEGRRef: data-element=P_AFA_bClsEGRRef.AFA_bClsEGRRef
          ds_AFA_rAirLdCorFil: data-element=P_AFA_rAirLdCorFil.AFA_rAirLdCorFil
          ds_AFA_bIdcCohLstObs: data-element=P_AFA_bIdcCohLstObs.AFA_bIdcCohLstObs
          ds_AFA_noObsDone: data-element=P_AFA_noObsDone.AFA_noObsDone
          ds_AFA_bEngStopAuth: data-element=P_AFA_bEngStopAuth.AFA_bEngStopAuth
          ds_AFA_facIvsInjGain: data-element=P_AFA_facIvsInjGain.AFA_facIvsInjGain
          ds_AFA_facArEffThrOfs2: data-element=P_AFA_facArEffThrOfs2.AFA_facArEffThrOfs2
          ds_AFA_agCkOpInVlvOfs: data-element=P_AFA_agCkOpInVlvOfs.AFA_agCkOpInVlvOfs
          ds_AFA_noRstAdpVal: data-element=P_AFA_noRstAdpVal.AFA_noRstAdpVal
          ds_AFA_bFitZeroPosnThr: data-element=P_AFA_bFitZeroPosnThr.AFA_bFitZeroPosnThr
          ds_AFA_arEffThrOfs: data-element=P_AFA_arEffThrOfs.AFA_arEffThrOfs
          ds_AFA_facArEffThrOfs3: data-element=P_AFA_facArEffThrOfs3.AFA_facArEffThrOfs3
          ds_AFA_bInnovTestCohDone: data-element=P_AFA_bInnovTestCohDone.AFA_bInnovTestCohDone
          ds_AFA_agCkClsExVlvOfs: data-element=P_AFA_agCkClsExVlvOfs.AFA_agCkClsExVlvOfs
          ds_AFA_nEngLstObs: data-element=P_AFA_nEngLstObs.AFA_nEngLstObs
          ds_AFA_prm_covErrEstim: data-element=P_AFA_prm_covErrEstim.AFA_prm_covErrEstim
          ds_AFA_tiDlyLstObs: data-element=P_AFA_tiDlyLstObs.AFA_tiDlyLstObs
          ds_AFA_arEffEGRVlvOfs: data-element=P_AFA_arEffEGRVlvOfs.AFA_arEffEGRVlvOfs
          ds_AFA_bAuthClsCanPurg: data-element=P_AFA_bAuthClsCanPurg.AFA_bAuthClsCanPurg
          ds_AFA_tiOffInj: data-element=P_AFA_tiOffInj.AFA_tiOffInj
          ds_AFA_noAdpEfcAst: data-element=P_AFA_noAdpEfcAst.AFA_noAdpEfcAst
          ds_AFA_facArEffThrOfs1: data-element=P_AFA_facArEffThrOfs1.AFA_facArEffThrOfs1
          ds_AFA_bFitOpInVlvBol: data-element=P_AFA_bFitOpInVlvBol.AFA_bFitOpInVlvBol
          ds_AFA_rCor_arEffEGRVlv: data-element=P_AFA_rCor_arEffEGRVlv.AFA_rCor_arEffEGRVlv
          ds_AFA_noAdpEfc: data-element=P_AFA_noAdpEfc.AFA_noAdpEfc
          ds_AFA_noAdpClcRst: data-element=P_AFA_noAdpClcRst.AFA_noAdpClcRst
          ds_AFA_facSlopInjGain: data-element=P_AFA_facSlopInjGain.AFA_facSlopInjGain
          ds_AFA_rAirPresFil: data-element=P_AFA_rAirPresFil.AFA_rAirPresFil
          ds_AFA_rTotLdCorLstObs: data-element=P_AFA_rTotLdCorLstObs.AFA_rTotLdCorLstObs
          ds_AFA_bAcvSpcInjMod: data-element=P_AFA_bAcvSpcInjMod.AFA_bAcvSpcInjMod
  swc implementation Imp_AFAT: code-generator=Real-Time Workshop Embedded Coder 5.5 (R2010a) 25-Jan-2010, programming-language=C, behavior=IB_AFAT
    code-descriptors:
      code CodeDescriptor: type=SRC
        241 x xfile:
          AFA_F03_calcul_adaptatifs_import_h: url=AFA_F03_calcul_adaptatifs_import.h
          AFA_F09_offset_air_load_h: url=AFA_F09_offset_air_load.h
          AFA_F01_add_cranking_noise_import_h: url=AFA_F01_add_cranking_noise_import.h
          AFA_F02_calc_sensitivity_mat_c: url=AFA_F02_calc_sensitivity_mat.c
          AFA_F05_Slop_air_load_import_h: url=AFA_F05_Slop_air_load_import.h
          AFA_F01_scruter_environ_adaptation_private_h: url=AFA_F01_scruter_environ_adaptation_private.h
          AFA_F06_calc_gain_de_kalman_h: url=AFA_F06_calc_gain_de_kalman.h
          AFA_F01_Osbservation_Number_private_h: url=AFA_F01_Osbservation_Number_private.h
          AFA_F03_reset_cumulated_model_noise_v_h: url=AFA_F03_reset_cumulated_model_noise_v.h
          AFA_F03_Slop_correction_private_h: url=AFA_F03_Slop_correction_private.h
          AFA_F00_init_scruter_environ_adaptation_h: url=AFA_F00_init_scruter_environ_adaptation.h
          AFA_F07_calc_error_param_vect_h: url=AFA_F07_calc_error_param_vect.h
          AFA_F01_scruter_environ_adaptation_import_h: url=AFA_F01_scruter_environ_adaptation_import.h
          AFA_F04_Water_correction_temperature_private_h: url=AFA_F04_Water_correction_temperature_private.h
          AFA_F01_lire_adaptatifs_en_eeprom_types_h: url=AFA_F01_lire_adaptatifs_en_eeprom_types.h
          AFA_F01_fresh_gas_temperature_private_h: url=AFA_F01_fresh_gas_temperature_private.h
          AFAT_Def_c: url=AFAT_Def.c
          AFA_F02_cylinder_volume_at_close_intake_valve_types_h: url=AFA_F02_cylinder_volume_at_close_intake_valve_types.h
          AFA_F06_Calc_Sensitivity_VVT_c: url=AFA_F06_Calc_Sensitivity_VVT.c
          AFA_F02_calc_model_noise_mat_types_h: url=AFA_F02_calc_model_noise_mat_types.h
          AFA_F00_init_scruter_environ_adaptation_c: url=AFA_F00_init_scruter_environ_adaptation.c
          AFAT_types_h: url=AFAT_types.h
          AFAT_import_h: url=AFAT_import.h
          AFA_F05_add_incoherence_model_noise_import_h: url=AFA_F05_add_incoherence_model_noise_import.h
          AFA_F03_add_throttle_reference_noise_private_h: url=AFA_F03_add_throttle_reference_noise_private.h
          AFA_F01_add_cranking_noise_private_h: url=AFA_F01_add_cranking_noise_private.h
          AFA_F05_add_incoherence_model_noise_types_h: url=AFA_F05_add_incoherence_model_noise_types.h
          AFA_F02_cylinder_volume_at_close_intake_valve_private_h: url=AFA_F02_cylinder_volume_at_close_intake_valve_private.h
          AFA_F01_reinit_after_app_adaption_h: url=AFA_F01_reinit_after_app_adaption.h
          AFA_F01_Calc_Sensitivity_SaintVenant_import_h: url=AFA_F01_Calc_Sensitivity_SaintVenant_import.h
          AFA_F04_detect_adaptation_stop_types_h: url=AFA_F04_detect_adaptation_stop_types.h
          AFA_F03_Calc_Sensitivity_Inj_h: url=AFA_F03_Calc_Sensitivity_Inj.h
          AFA_F04_add_egr_reference_noise_private_h: url=AFA_F04_add_egr_reference_noise_private.h
          AFA_F05_Calc_Sensitivity_EGR_c: url=AFA_F05_Calc_Sensitivity_EGR.c
          AFA_F01_scruter_environ_adaptation_types_h: url=AFA_F01_scruter_environ_adaptation_types.h
          AFA_F08_calc_est_error_covar_mat_c: url=AFA_F08_calc_est_error_covar_mat.c
          AFA_F04_command_adaptation_parameters_h: url=AFA_F04_command_adaptation_parameters.h
          AFA_F01_calc_measurement_vector_c: url=AFA_F01_calc_measurement_vector.c
          AFA_F09_offset_air_load_c: url=AFA_F09_offset_air_load.c
          AFA_F01_calc_measurement_vector_h: url=AFA_F01_calc_measurement_vector.h
          AFA_F02_Afa_adapt_terms_reset_c: url=AFA_F02_Afa_adapt_terms_reset.c
          AFA_F03_calcul_adaptatifs_c: url=AFA_F03_calcul_adaptatifs.c
          AFA_F01_Calc_Sensitivity_SaintVenant_private_h: url=AFA_F01_Calc_Sensitivity_SaintVenant_private.h
          AFA_F01_AFAClcObs_c: url=AFA_F01_AFAClcObs.c
          AFA_F08_add_EVC_reference_noise_types_h: url=AFA_F08_add_EVC_reference_noise_types.h
          AFA_F02_Afa_adapt_terms_reset_private_h: url=AFA_F02_Afa_adapt_terms_reset_private.h
          AFA_F07_add_IVO_reference_noise_c: url=AFA_F07_add_IVO_reference_noise.c
          AFA_F07_Residual_scavenged_reaspired_mass_data_c: url=AFA_F07_Residual_scavenged_reaspired_mass_data.c
          AFA_F06_Calc_Sensitivity_VVT_private_h: url=AFA_F06_Calc_Sensitivity_VVT_private.h
          AFA_F01_init_inputs_filters_c: url=AFA_F01_init_inputs_filters.c
          AFA_F10_Total_load_gradient_h: url=AFA_F10_Total_load_gradient.h
          AFA_F02_Activation_EOM_Mode_import_h: url=AFA_F02_Activation_EOM_Mode_import.h
          AFA_F02_inputs_filters_private_h: url=AFA_F02_inputs_filters_private.h
          AFA_F05_Calc_Sensitivity_EGR_import_h: url=AFA_F05_Calc_Sensitivity_EGR_import.h
          AFA_F02_calc_sensitivity_mat_h: url=AFA_F02_calc_sensitivity_mat.h
          AFA_F05_add_incoherence_model_noise_h: url=AFA_F05_add_incoherence_model_noise.h
          AFA_F02_Calc_sensitivity_load_estim_import_h: url=AFA_F02_Calc_sensitivity_load_estim_import.h
          AFA_F05_add_incoherence_model_noise_private_h: url=AFA_F05_add_incoherence_model_noise_private.h
          AFA_F04_Calc_Sensitivity_Pap_h: url=AFA_F04_Calc_Sensitivity_Pap.h
          AFA_F02_Activation_EOM_Mode_h: url=AFA_F02_Activation_EOM_Mode.h
          AFA_F04_detect_adaptation_stop_c: url=AFA_F04_detect_adaptation_stop.c
          AFA_F02_calc_model_noise_mat_private_h: url=AFA_F02_calc_model_noise_mat_private.h
          AFA_F01_lire_adaptatifs_en_eeprom_private_h: url=AFA_F01_lire_adaptatifs_en_eeprom_private.h
          AFA_F03_add_throttle_reference_noise_h: url=AFA_F03_add_throttle_reference_noise.h
          AFA_F08_burn_gas_temperature_types_h: url=AFA_F08_burn_gas_temperature_types.h
          AFA_F05_Slop_air_load_h: url=AFA_F05_Slop_air_load.h
          AFA_F04_Water_correction_temperature_import_h: url=AFA_F04_Water_correction_temperature_import.h
          AFA_F05_Calc_Sensitivity_EGR_h: url=AFA_F05_Calc_Sensitivity_EGR.h
          AFA_F03_Calc_Sensitivity_Inj_private_h: url=AFA_F03_Calc_Sensitivity_Inj_private.h
          AFA_F06_Specific_VVT_angle_h: url=AFA_F06_Specific_VVT_angle.h
          AFA_F01_AFAClcObs_types_h: url=AFA_F01_AFAClcObs_types.h
          AFA_F04_command_adaptation_parameters_types_h: url=AFA_F04_command_adaptation_parameters_types.h
          AFA_F03_reset_cumulated_model_noise_v_types_h: url=AFA_F03_reset_cumulated_model_noise_v_types.h
          AFA_F06_add_adaption_noise_types_h: url=AFA_F06_add_adaption_noise_types.h
          AFA_F01_scruter_environ_adaptation_h: url=AFA_F01_scruter_environ_adaptation.h
          AFA_F04_Calc_Sensitivity_Pap_c: url=AFA_F04_Calc_Sensitivity_Pap.c
          AFA_F01_reinit_after_app_adaption_types_h: url=AFA_F01_reinit_after_app_adaption_types.h
          AFA_F01_init_inputs_filters_types_h: url=AFA_F01_init_inputs_filters_types.h
          AFA_F01_fresh_gas_temperature_types_h: url=AFA_F01_fresh_gas_temperature_types.h
          AFA_F06_Specific_VVT_angle_c: url=AFA_F06_Specific_VVT_angle.c
          AFA_F08_add_EVC_reference_noise_h: url=AFA_F08_add_EVC_reference_noise.h
          AFA_F02_Afa_adapt_terms_reset_import_h: url=AFA_F02_Afa_adapt_terms_reset_import.h
          AFA_F04_command_adaptation_parameters_private_h: url=AFA_F04_command_adaptation_parameters_private.h
          AFA_F03_Calc_Sensitivity_Inj_c: url=AFA_F03_Calc_Sensitivity_Inj.c
          AFA_F01_AFAClcObs_import_h: url=AFA_F01_AFAClcObs_import.h
          AFA_F03_Slop_correction_c: url=AFA_F03_Slop_correction.c
          AFA_F02_Calc_sensitivity_load_estim_h: url=AFA_F02_Calc_sensitivity_load_estim.h
          AFA_F08_burn_gas_temperature_private_h: url=AFA_F08_burn_gas_temperature_private.h
          AFA_F03_Slop_correction_h: url=AFA_F03_Slop_correction.h
          AFA_F04_calc_innovation_vect_types_h: url=AFA_F04_calc_innovation_vect_types.h
          AFA_F02_inputs_filters_import_h: url=AFA_F02_inputs_filters_import.h
          AFA_F02_Afa_adapt_terms_reset_h: url=AFA_F02_Afa_adapt_terms_reset.h
          AFA_F01_Calc_Sensitivity_SaintVenant_types_h: url=AFA_F01_Calc_Sensitivity_SaintVenant_types.h
          AFA_F05_Calc_Sensitivity_EGR_private_h: url=AFA_F05_Calc_Sensitivity_EGR_private.h
          AFA_F04_Water_correction_temperature_c: url=AFA_F04_Water_correction_temperature.c
          AFA_F02_add_patmo_reference_noise_h: url=AFA_F02_add_patmo_reference_noise.h
          AFA_F01_Calc_Sensitivity_SaintVenant_c: url=AFA_F01_Calc_Sensitivity_SaintVenant.c
          AFA_F07_add_IVO_reference_noise_types_h: url=AFA_F07_add_IVO_reference_noise_types.h
          AFA_F03_calcul_adaptatifs_private_h: url=AFA_F03_calcul_adaptatifs_private.h
          AFA_F02_add_patmo_reference_noise_types_h: url=AFA_F02_add_patmo_reference_noise_types.h
          AFA_F02_inputs_filters_types_h: url=AFA_F02_inputs_filters_types.h
          AFA_F04_add_egr_reference_noise_h: url=AFA_F04_add_egr_reference_noise.h
          AFA_F06_calc_gain_de_kalman_c: url=AFA_F06_calc_gain_de_kalman.c
          AFA_F01_fresh_gas_temperature_h: url=AFA_F01_fresh_gas_temperature.h
          AFA_F01_Osbservation_Number_c: url=AFA_F01_Osbservation_Number.c
          AFA_F01_Osbservation_Number_types_h: url=AFA_F01_Osbservation_Number_types.h
          AFA_F04_Water_correction_temperature_h: url=AFA_F04_Water_correction_temperature.h
          AFA_F04_calc_innovation_vect_private_h: url=AFA_F04_calc_innovation_vect_private.h
          AFA_F01_scruter_environ_adaptation_c: url=AFA_F01_scruter_environ_adaptation.c
          AFA_F01_calc_measurement_vector_types_h: url=AFA_F01_calc_measurement_vector_types.h
          AFA_F07_Residual_scavenged_reaspired_mass_types_h: url=AFA_F07_Residual_scavenged_reaspired_mass_types.h
          AFA_F05_calc_pred_innov_covar_mat_c: url=AFA_F05_calc_pred_innov_covar_mat.c
          AFA_F02_cylinder_volume_at_close_intake_valve_c: url=AFA_F02_cylinder_volume_at_close_intake_valve.c
          AFA_F03_Slop_correction_types_h: url=AFA_F03_Slop_correction_types.h
          AFA_F01_Osbservation_Number_import_h: url=AFA_F01_Osbservation_Number_import.h
          AFA_F04_detect_adaptation_stop_import_h: url=AFA_F04_detect_adaptation_stop_import.h
          AFA_F01_calc_measurement_vector_private_h: url=AFA_F01_calc_measurement_vector_private.h
          AFA_F06_Specific_VVT_angle_private_h: url=AFA_F06_Specific_VVT_angle_private.h
          AFA_F02_Activation_EOM_Mode_private_h: url=AFA_F02_Activation_EOM_Mode_private.h
          AFA_F05_Calc_Sensitivity_EGR_types_h: url=AFA_F05_Calc_Sensitivity_EGR_types.h
          AFA_F03_Calc_Sensitivity_Inj_import_h: url=AFA_F03_Calc_Sensitivity_Inj_import.h
          AFA_F01_lire_adaptatifs_en_eeprom_c: url=AFA_F01_lire_adaptatifs_en_eeprom.c
          AFAT_nvm_c: url=AFAT_nvm.c
          AFA_F07_calc_error_param_vect_c: url=AFA_F07_calc_error_param_vect.c
          AFA_F06_add_adaption_noise_c: url=AFA_F06_add_adaption_noise.c
          AFA_F04_detect_adaptation_stop_private_h: url=AFA_F04_detect_adaptation_stop_private.h
          AFAT_h: url=AFAT.h
          AFA_F06_Calc_Sensitivity_VVT_types_h: url=AFA_F06_Calc_Sensitivity_VVT_types.h
          AFA_F05_Slop_air_load_private_h: url=AFA_F05_Slop_air_load_private.h
          AFA_F06_calc_gain_de_kalman_data_c: url=AFA_F06_calc_gain_de_kalman_data.c
          AFA_F01_init_inputs_filters_h: url=AFA_F01_init_inputs_filters.h
          AFAT_c: url=AFAT.c
          AFA_F02_calc_model_noise_mat_h: url=AFA_F02_calc_model_noise_mat.h
          AFA_F02_cylinder_volume_at_close_intake_valve_import_h: url=AFA_F02_cylinder_volume_at_close_intake_valve_import.h
          AFA_F08_add_EVC_reference_noise_c: url=AFA_F08_add_EVC_reference_noise.c
          AFA_F04_add_egr_reference_noise_c: url=AFA_F04_add_egr_reference_noise.c
          AFA_F07_add_IVO_reference_noise_private_h: url=AFA_F07_add_IVO_reference_noise_private.h
          AFA_F02_cylinder_volume_at_close_intake_valve_h: url=AFA_F02_cylinder_volume_at_close_intake_valve.h
          AFA_F03_reset_cumulated_model_noise_v_data_c: url=AFA_F03_reset_cumulated_model_noise_v_data.c
          AFA_F01_fresh_gas_temperature_c: url=AFA_F01_fresh_gas_temperature.c
          AFA_F08_add_EVC_reference_noise_private_h: url=AFA_F08_add_EVC_reference_noise_private.h
          AFA_F05_calc_pred_innov_covar_mat_h: url=AFA_F05_calc_pred_innov_covar_mat.h
          AFA_F02_inputs_filters_h: url=AFA_F02_inputs_filters.h
          AFA_F02_add_patmo_reference_noise_import_h: url=AFA_F02_add_patmo_reference_noise_import.h
          AFAT_Version_c: url=AFAT_Version.c
          AFA_F05_calc_pred_innov_covar_mat_private_h: url=AFA_F05_calc_pred_innov_covar_mat_private.h
          AFA_F01_add_cranking_noise_types_h: url=AFA_F01_add_cranking_noise_types.h
          AFA_F08_calc_est_error_covar_mat_private_h: url=AFA_F08_calc_est_error_covar_mat_private.h
          AFA_F04_calc_innovation_vect_c: url=AFA_F04_calc_innovation_vect.c
          AFA_F06_calc_gain_de_kalman_types_h: url=AFA_F06_calc_gain_de_kalman_types.h
          AFAT_MemMap_h: url=AFAT_MemMap.h
          AFA_F01_Calc_Sensitivity_SaintVenant_h: url=AFA_F01_Calc_Sensitivity_SaintVenant.h
          AFA_F02_add_patmo_reference_noise_c: url=AFA_F02_add_patmo_reference_noise.c
          AFA_F02_calc_model_noise_mat_c: url=AFA_F02_calc_model_noise_mat.c
          AFA_F01_init_inputs_filters_private_h: url=AFA_F01_init_inputs_filters_private.h
          AFA_F03_reset_cumulated_model_noise_v_private_h: url=AFA_F03_reset_cumulated_model_noise_v_private.h
          AFA_F01_lire_adaptatifs_en_eeprom_h: url=AFA_F01_lire_adaptatifs_en_eeprom.h
          AFA_F05_calc_pred_innov_covar_mat_types_h: url=AFA_F05_calc_pred_innov_covar_mat_types.h
          AFA_F07_calc_error_param_vect_types_h: url=AFA_F07_calc_error_param_vect_types.h
          AFA_F08_burn_gas_temperature_c: url=AFA_F08_burn_gas_temperature.c
          AFA_F06_add_adaption_noise_import_h: url=AFA_F06_add_adaption_noise_import.h
          AFA_F08_calc_est_error_covar_mat_h: url=AFA_F08_calc_est_error_covar_mat.h
          AFA_F06_tempos_adaptation_types_h: url=AFA_F06_tempos_adaptation_types.h
          AFA_F06_tempos_adaptation_import_h: url=AFA_F06_tempos_adaptation_import.h
          AFA_F06_Calc_Sensitivity_VVT_h: url=AFA_F06_Calc_Sensitivity_VVT.h
          AFA_F05_Slop_air_load_types_h: url=AFA_F05_Slop_air_load_types.h
          AFA_F01_calc_measurement_vector_import_h: url=AFA_F01_calc_measurement_vector_import.h
          AFA_F03_Slop_correction_import_h: url=AFA_F03_Slop_correction_import.h
          AFA_F01_reinit_after_app_adaption_private_h: url=AFA_F01_reinit_after_app_adaption_private.h
          AFA_F00_init_scruter_environ_adaptation_types_h: url=AFA_F00_init_scruter_environ_adaptation_types.h
          AFA_F09_offset_air_load_types_h: url=AFA_F09_offset_air_load_types.h
          AFA_F08_calc_est_error_covar_mat_types_h: url=AFA_F08_calc_est_error_covar_mat_types.h
          AFA_F03_add_throttle_reference_noise_c: url=AFA_F03_add_throttle_reference_noise.c
          AFA_F10_Total_load_gradient_private_h: url=AFA_F10_Total_load_gradient_private.h
          AFA_F06_add_adaption_noise_private_h: url=AFA_F06_add_adaption_noise_private.h
          AFA_F06_add_adaption_noise_h: url=AFA_F06_add_adaption_noise.h
          AFA_F06_tempos_adaptation_c: url=AFA_F06_tempos_adaptation.c
          AFA_F01_AFAClcObs_private_h: url=AFA_F01_AFAClcObs_private.h
          AFA_F06_tempos_adaptation_private_h: url=AFA_F06_tempos_adaptation_private.h
          AFAT_Version_h: url=AFAT_Version.h
          AFA_F07_Residual_scavenged_reaspired_mass_private_h: url=AFA_F07_Residual_scavenged_reaspired_mass_private.h
          AFA_F02_calc_sensitivity_mat_types_h: url=AFA_F02_calc_sensitivity_mat_types.h
          AFA_F02_calc_sensitivity_mat_import_h: url=AFA_F02_calc_sensitivity_mat_import.h
          AFA_F06_calc_gain_de_kalman_private_h: url=AFA_F06_calc_gain_de_kalman_private.h
          AFA_F01_Osbservation_Number_h: url=AFA_F01_Osbservation_Number.h
          AFA_F02_calc_sensitivity_mat_private_h: url=AFA_F02_calc_sensitivity_mat_private.h
          AFA_F04_calc_innovation_vect_h: url=AFA_F04_calc_innovation_vect.h
          AFA_F02_Calc_sensitivity_load_estim_types_h: url=AFA_F02_Calc_sensitivity_load_estim_types.h
          AFA_F07_Residual_scavenged_reaspired_mass_import_h: url=AFA_F07_Residual_scavenged_reaspired_mass_import.h
          AFA_F04_Calc_Sensitivity_Pap_import_h: url=AFA_F04_Calc_Sensitivity_Pap_import.h
          AFA_F06_tempos_adaptation_h: url=AFA_F06_tempos_adaptation.h
          AFA_F01_fresh_gas_temperature_import_h: url=AFA_F01_fresh_gas_temperature_import.h
          AFA_F00_init_scruter_environ_adaptation_private_h: url=AFA_F00_init_scruter_environ_adaptation_private.h
          AFA_F05_Slop_air_load_c: url=AFA_F05_Slop_air_load.c
          AFA_F03_Calc_Sensitivity_Inj_types_h: url=AFA_F03_Calc_Sensitivity_Inj_types.h
          AFA_F01_reinit_after_app_adaption_c: url=AFA_F01_reinit_after_app_adaption.c
          AFA_F02_Activation_EOM_Mode_c: url=AFA_F02_Activation_EOM_Mode.c
          AFA_F01_reinit_after_app_adaption_data_c: url=AFA_F01_reinit_after_app_adaption_data.c
          AFA_F04_command_adaptation_parameters_c: url=AFA_F04_command_adaptation_parameters.c
          AFA_F06_Specific_VVT_angle_types_h: url=AFA_F06_Specific_VVT_angle_types.h
          AFA_F01_add_cranking_noise_h: url=AFA_F01_add_cranking_noise.h
          AFA_F09_offset_air_load_private_h: url=AFA_F09_offset_air_load_private.h
          AFA_F07_calc_error_param_vect_private_h: url=AFA_F07_calc_error_param_vect_private.h
          AFA_F04_Calc_Sensitivity_Pap_types_h: url=AFA_F04_Calc_Sensitivity_Pap_types.h
          AFA_F07_add_IVO_reference_noise_import_h: url=AFA_F07_add_IVO_reference_noise_import.h
          AFA_F07_Residual_scavenged_reaspired_mass_h: url=AFA_F07_Residual_scavenged_reaspired_mass.h
          AFAT_nvm_h: url=AFAT_nvm.h
          AFA_F08_burn_gas_temperature_import_h: url=AFA_F08_burn_gas_temperature_import.h
          AFA_F05_calc_pred_innov_covar_mat_import_h: url=AFA_F05_calc_pred_innov_covar_mat_import.h
          AFAT_private_h: url=AFAT_private.h
          AFA_F07_add_IVO_reference_noise_h: url=AFA_F07_add_IVO_reference_noise.h
          AFA_F08_burn_gas_temperature_h: url=AFA_F08_burn_gas_temperature.h
          AFA_F04_command_adaptation_parameters_import_h: url=AFA_F04_command_adaptation_parameters_import.h
          AFA_F04_add_egr_reference_noise_types_h: url=AFA_F04_add_egr_reference_noise_types.h
          AFA_F03_add_throttle_reference_noise_types_h: url=AFA_F03_add_throttle_reference_noise_types.h
          AFA_F10_Total_load_gradient_types_h: url=AFA_F10_Total_load_gradient_types.h
          AFA_F03_reset_cumulated_model_noise_v_c: url=AFA_F03_reset_cumulated_model_noise_v.c
          AFA_F03_add_throttle_reference_noise_import_h: url=AFA_F03_add_throttle_reference_noise_import.h
          AFA_F03_calcul_adaptatifs_h: url=AFA_F03_calcul_adaptatifs.h
          AFA_F10_Total_load_gradient_c: url=AFA_F10_Total_load_gradient.c
          AFA_F04_detect_adaptation_stop_h: url=AFA_F04_detect_adaptation_stop.h
          AFA_F01_AFAClcObs_h: url=AFA_F01_AFAClcObs.h
          AFA_F08_add_EVC_reference_noise_import_h: url=AFA_F08_add_EVC_reference_noise_import.h
          AFA_F02_inputs_filters_c: url=AFA_F02_inputs_filters.c
          AFA_F08_calc_est_error_covar_mat_data_c: url=AFA_F08_calc_est_error_covar_mat_data.c
          AFA_F04_add_egr_reference_noise_import_h: url=AFA_F04_add_egr_reference_noise_import.h
          AFA_F02_Calc_sensitivity_load_estim_c: url=AFA_F02_Calc_sensitivity_load_estim.c
          AFA_F02_Calc_sensitivity_load_estim_private_h: url=AFA_F02_Calc_sensitivity_load_estim_private.h
          AFA_F01_add_cranking_noise_c: url=AFA_F01_add_cranking_noise.c
          AFA_F04_Water_correction_temperature_types_h: url=AFA_F04_Water_correction_temperature_types.h
          AFA_F06_Calc_Sensitivity_VVT_import_h: url=AFA_F06_Calc_Sensitivity_VVT_import.h
          AFA_F04_Calc_Sensitivity_Pap_private_h: url=AFA_F04_Calc_Sensitivity_Pap_private.h
          AFA_F07_Residual_scavenged_reaspired_mass_c: url=AFA_F07_Residual_scavenged_reaspired_mass.c
          AFA_F08_calc_est_error_covar_mat_import_h: url=AFA_F08_calc_est_error_covar_mat_import.h
          AFA_F01_reinit_after_app_adaption_import_h: url=AFA_F01_reinit_after_app_adaption_import.h
          AFA_F02_Afa_adapt_terms_reset_types_h: url=AFA_F02_Afa_adapt_terms_reset_types.h
          AFA_F05_add_incoherence_model_noise_c: url=AFA_F05_add_incoherence_model_noise.c
          AFA_F03_calcul_adaptatifs_types_h: url=AFA_F03_calcul_adaptatifs_types.h
          AFA_F02_Activation_EOM_Mode_types_h: url=AFA_F02_Activation_EOM_Mode_types.h
          AFAT_data_c: url=AFAT_data.c
          AFA_F02_add_patmo_reference_noise_private_h: url=AFA_F02_add_patmo_reference_noise_private.h
package /Components/SWC_AFAT/AFAT_IRVDatatypes
  5 x boolean type, all with base-type=boolean:
    DT_AFA_bAdpClcRstReqHld_irv
    DT_AFA_bAFAClcMdlNoise_irv
    DT_AFA_bIdcInv_covPredInnov_irv
    DT_AFA_bRstAdpTerm_irv
    DT_AFA_bRstAdpTermMem_irv
  32 x integer type:
    DT_AFA_agCkClsExVlvBolHld_irv: base-type=uint16, lower-limit=0, upper-limit=65535
    DT_AFA_agCkClsExVlvEstimRef1Fil_irv: base-type=int16, lower-limit=-32768, upper-limit=32767
    DT_AFA_agCkClsInVlvEstimRef1Fil_irv: base-type=uint16, lower-limit=0, upper-limit=65535
    DT_AFA_agCkOpInVlvBolHld_irv: base-type=uint16, lower-limit=0, upper-limit=65535
    DT_AFA_agCkOpInVlvEstimRef1Fil_irv: base-type=int16, lower-limit=-32768, upper-limit=32767
    DT_AFA_arEffAdpEGRVlvFil_irv: base-type=uint16, lower-limit=0, upper-limit=65535
    DT_AFA_arEffAdpThrFil_irv: base-type=uint16, lower-limit=0, upper-limit=65535
    DT_AFA_arEffEGRVlvFil_irv: base-type=uint16, lower-limit=0, upper-limit=65535
    DT_AFA_facRhoFuFil_irv: base-type=uint8, lower-limit=0, upper-limit=255
    DT_AFA_facSlopEfcCorFil_irv: base-type=uint32, lower-limit=0, upper-limit=4294967295
    DT_AFA_mFuReqFil_irv: base-type=uint32, lower-limit=0, upper-limit=4294967295
    DT_AFA_nEngCorFil_irv: base-type=uint16, lower-limit=0, upper-limit=65535
    DT_AFA_nEngFil_irv: base-type=uint16, lower-limit=0, upper-limit=65535
    DT_AFA_noObsDoneIdlIni_irv: base-type=uint8, lower-limit=0, upper-limit=255
    DT_AFA_noObsInnovNotCoh_irv: base-type=uint8, lower-limit=0, upper-limit=255
    DT_AFA_noObsSpcInjMod_irv: base-type=uint8, lower-limit=0, upper-limit=255
    DT_AFA_pAirExtEstimFil_irv: base-type=uint16, lower-limit=0, upper-limit=65535
    DT_AFA_pAirExtEstimHld_irv: base-type=uint16, lower-limit=0, upper-limit=65535
    DT_AFA_pDsThrCorFil_irv: base-type=uint16, lower-limit=0, upper-limit=65535
    DT_AFA_pDsThrEstimErrFil_irv: base-type=int16, lower-limit=-32768, upper-limit=32767
    DT_AFA_pDsThrEstimFil_irv: base-type=uint16, lower-limit=0, upper-limit=65535
    DT_AFA_pDsThrPred_facVlvOvlpFil_irv: base-type=uint16, lower-limit=0, upper-limit=65535
    DT_AFA_pExMnfEstimFil_irv: base-type=uint16, lower-limit=0, upper-limit=65535
    DT_AFA_rEthStoichFil_irv: base-type=uint16, lower-limit=0, upper-limit=65535
    DT_AFA_rInMassFlowFil_irv: base-type=uint16, lower-limit=0, upper-limit=65535
    DT_AFA_rOpClsEGRVlvBolHld_irv: base-type=uint16, lower-limit=0, upper-limit=65535
    DT_AFA_rOpClsThrBolHld_irv: base-type=uint16, lower-limit=0, upper-limit=65535
    DT_AFA_rOpSIFil_irv: base-type=uint16, lower-limit=0, upper-limit=65535
    DT_AFA_rTotLdExCorFil_irv: base-type=uint16, lower-limit=0, upper-limit=65535
    DT_AFA_tAirUsInVlvEstimFil_irv: base-type=uint32, lower-limit=0, upper-limit=4294967295
    DT_AFA_tCoMesFil_irv: base-type=int16, lower-limit=-32768, upper-limit=32767
    DT_AFA_tExMnfEstimFil_irv: base-type=uint16, lower-limit=0, upper-limit=65535
package /Components/SWC_AFAT/AFAT_PIMDatatypes
  9 x array type:
    rt_Array_Boolean_16_m0
      element ArrayElement: base-type=boolean, type=Boolean, max-number-of-elements=16
    rt_Array_SInt16_16_m0
      element ArrayElement: base-type=int16, type=SInt16, max-number-of-elements=16
    rt_Array_SInt16_2_m0
      element ArrayElement: base-type=int16, type=SInt16, max-number-of-elements=2
    rt_Array_SInt16_8_m0
      element ArrayElement: base-type=int16, type=SInt16, max-number-of-elements=8
    rt_Array_SInt32_16_m0
      element ArrayElement: base-type=int32, type=SInt32, max-number-of-elements=16
    rt_Array_UInt16_64_m0
      element ArrayElement: base-type=uint16, type=UInt16, max-number-of-elements=64
    rt_Array_UInt32_4_m0
      element ArrayElement: base-type=uint32, type=UInt32, max-number-of-elements=4
    rt_Array_UInt8_4_m0
      element ArrayElement: base-type=uint8, type=UInt8, max-number-of-elements=4
    rt_Array_UInt8_9_m0
      element ArrayElement: base-type=uint8, type=UInt8, max-number-of-elements=9
